VERSION ""

NS_ :

BS_:

BU_: TE DCU Dash BMS IIB ISA Interface AHRSF AHRSR GPSF GPSR

BO_ 329 TE_MAIN: 8 TE
 SG_ apps : 16|16@1+ (0.01,0) [0|10000] "percentage"  TE
 SG_ bps_pressure : 32|16@1+ (0.01,0) [0|10000] "percentage"  TE
 SG_ bps_electric : 48|16@1+ (0.01,0) [0|10000] "percentage"  TE
 SG_ cc_apps_0 : 0|1@1+ (1,0) [0|1] ""  TE
 SG_ cc_apps_1 : 1|1@1+ (1,0) [0|0] ""  TE
 SG_ cc_bps_eletric_0 : 2|1@1+ (1,0) [0|0] ""  TE
 SG_ cc_bps_pressure_0 : 3|1@1+ (1,0) [0|0] ""  TE
 SG_ cc_bps_pressure_1 : 4|1@1+ (1,0) [0|0] ""  TE
 SG_ overshoot_apps_0 : 5|1@1+ (1,0) [0|0] ""  TE
 SG_ overshoot_apps_1 : 6|1@1+ (1,0) [0|0] ""  TE
 SG_ Overshoot_BPS_eletric : 7|1@1+ (1,0) [0|0] ""  TE
 SG_ imp_apps_timer_exceeded : 8|1@1+ (1,0) [0|0] ""  TE
 SG_ imp_apps_bps_timer_exceeded : 9|1@1+ (1,0) [0|0] ""  TE
 SG_ hard_braking : 10|1@1+ (1,0) [0|0] ""  TE
 SG_ sc_motor_interlock_front : 11|1@1+ (1,0) [0|0] ""  TE
 SG_ te_verbose_mode : 12|1@1+ (1,0) [0|0] ""  TE
 SG_ implausibility_apps : 13|1@1+ (1,0) [0|0] ""  TE
 SG_ implausibility_apps_bps : 14|1@1+ (1,0) [0|0] ""  TE

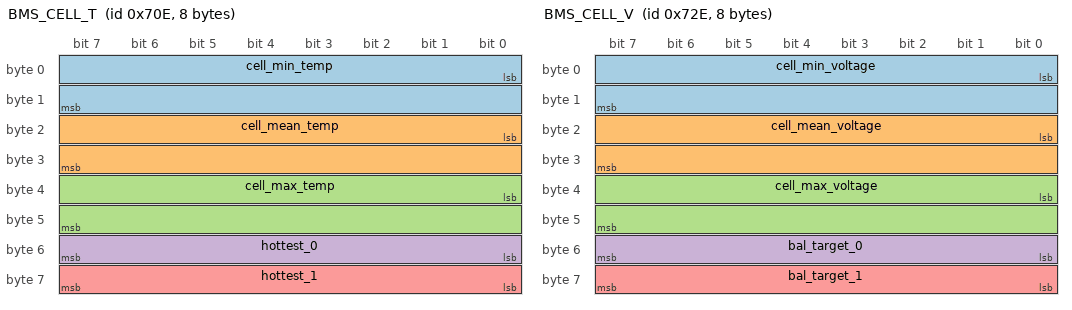
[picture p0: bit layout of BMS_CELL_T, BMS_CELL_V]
BO_ 1806 BMS_CELL_T: 8 BMS
 SG_ cell_min_temp : 0|16@1+ (0.1,0) [0|0] "C"  BMS
 SG_ cell_mean_temp : 16|16@1+ (0.1,0) [0|0] "C"  BMS
 SG_ cell_max_temp : 32|16@1+ (0.1,0) [0|0] "C"  BMS
 SG_ hottest_0 : 48|8@1+ (1,0) [0|12] ""  BMS
 SG_ hottest_1 : 56|8@1+ (1,0) [0|12] ""  BMS

BO_ 1838 BMS_CELL_V: 8 BMS
 SG_ cell_min_voltage : 0|16@1+ (1,0) [0|0] ""  BMS
 SG_ cell_mean_voltage : 16|16@1+ (1,0) [0|0] ""  BMS
 SG_ cell_max_voltage : 32|16@1+ (1,0) [0|0] ""  BMS
 SG_ bal_target_0 : 48|8@1+ (1,0) [0|0] ""  BMS
 SG_ bal_target_1 : 56|8@1+ (1,0) [0|0] ""  BMS

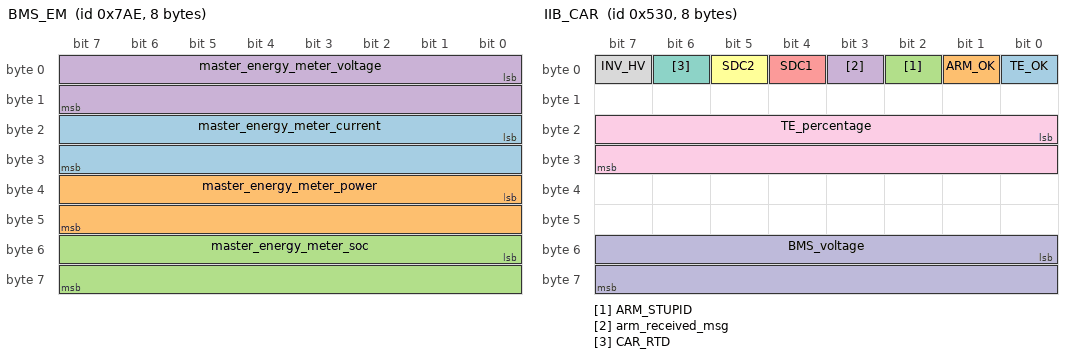
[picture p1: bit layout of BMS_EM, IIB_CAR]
BO_ 1966 BMS_EM: 8 BMS
 SG_ master_energy_meter_current : 16|16@1- (1,0) [0|0] "A"  BMS
 SG_ master_energy_meter_power : 32|16@1- (1,0) [0|0] "W"  BMS
 SG_ master_energy_meter_soc : 48|16@1+ (1,0) [0|0] "%"  BMS
 SG_ master_energy_meter_voltage : 0|16@1+ (1,0) [0|0] "V"  BMS

BO_ 398 BMS_TS_STATE: 2 BMS
 SG_ state : 0|1@1+ (1,0) [0|0] ""  BMS
 SG_ reason : 1|7@1+ (1,0) [0|0] ""  BMS

BO_ 494 BMS_STATUS: 4 BMS
 SG_ AMS_OK : 0|1@1+ (1,0) [0|0] ""  BMS
 SG_ IMD_OK : 1|1@1+ (1,0) [0|0] ""  BMS
 SG_ IMD_LATCH : 2|1@1+ (1,0) [0|0] ""  BMS
 SG_ AMS_LATCH : 3|1@1+ (1,0) [0|0] ""  BMS
 SG_ AIR_negative : 4|1@1+ (1,0) [0|0] ""  BMS
 SG_ PreChK : 6|1@1+ (1,0) [0|0] ""  BMS
 SG_ DisChK : 7|1@1+ (1,0) [0|0] ""  BMS
 SG_ SC_DCU_IMD : 8|1@1+ (1,0) [0|0] ""  BMS
 SG_ SC_IMD_AMS : 9|1@1+ (1,0) [0|0] ""  BMS
 SG_ SC_AMS_DCU : 10|1@1+ (1,0) [0|0] ""  BMS
 SG_ SC_TSMS_Relays : 11|1@1+ (1,0) [0|0] ""  BMS
 SG_ shutdown_above_minimum : 12|1@1+ (1,0) [0|0] ""  BMS
 SG_ shutdown_open : 13|1@1+ (1,0) [0|0] ""  BMS
 SG_ verbose : 14|1@1+ (1,0) [0|0] ""  BMS
 SG_ ts_on : 15|1@1+ (1,0) [0|0] ""  BMS
 SG_ AIR_positive : 5|1@1+ (1,0) [0|0] ""  BMS
 SG_ PRECH_END_SIG : 16|16@1+ (1,0) [0|0] "" Vector__XXX

BO_ 1296 IIB_LIMITS: 8 IIB
 SG_ limit_motor_num M : 14|2@1+ (1,0) [0|3] ""  IIB
 SG_ max_safety_power m0 : 0|8@1+ (1,0) [0|255] "kW"  IIB
 SG_ max_operation_power m0 : 16|16@1+ (1,0) [0|0] "kW"  IIB
 SG_ max_safety_torque m0 : 32|16@1+ (0.001,0) [0|0] "Nm"  IIB
 SG_ max_operation_torque m0 : 48|16@1+ (0.001,0) [0|0] "Nm"  IIB
 SG_ max_safety_power m1 : 0|8@1+ (1,0) [0|0] "kW"  IIB
 SG_ max_operation_power m1 : 16|16@1+ (1,0) [0|0] "kW"  IIB
 SG_ max_safety_torque m1 : 32|16@1+ (0.001,0) [0|0] "Nm"  IIB
 SG_ max_operation_torque m1 : 48|16@1+ (0.001,0) [0|0] "Nm"  IIB
 SG_ max_safety_power m2 : 0|8@1+ (1,0) [0|0] "kW"  IIB
 SG_ max_operation_power m2 : 16|16@1+ (1,0) [0|0] "kW"  IIB
 SG_ max_safety_torque m2 : 32|16@1+ (0.001,0) [0|0] "Nm"  IIB
 SG_ max_operation_torque m2 : 48|16@1+ (0.001,0) [0|0] "Nm"  IIB
 SG_ max_safety_power m3 : 0|8@1+ (1,0) [0|0] "kW"  IIB
 SG_ max_operation_power m3 : 16|16@1+ (1,0) [0|0] "kW"  IIB
 SG_ max_operation_torque m3 : 48|16@1+ (0.001,0) [0|0] "Nm"  IIB
 SG_ max_safety_torque m3: 32|16@1+ (0.001,0) [0|0] "Nm"  IIB

BO_ 1328 IIB_CAR: 8 IIB
 SG_ TE_OK : 0|1@1+ (1,0) [0|0] ""  IIB
 SG_ ARM_OK : 1|1@1+ (1,0) [0|0] ""  IIB
 SG_ ARM_STUPID : 2|1@1+ (1,0) [0|0] ""  IIB
 SG_ arm_received_msg : 3|1@1+ (1,0) [0|0] ""  IIB
 SG_ SDC1 : 4|1@1+ (1,0) [0|0] ""  IIB
 SG_ SDC2 : 5|1@1+ (1,0) [0|0] ""  IIB
 SG_ CAR_RTD : 6|1@1+ (1,0) [0|0] ""  IIB
 SG_ INV_HV : 7|1@1+ (1,0) [0|0] ""  IIB
 SG_ TE_percentage : 16|16@1+ (1,0) [0|0] "percentage"  IIB
 SG_ BMS_voltage : 48|16@1+ (1,0) [0|0] "volts"  IIB

BO_ 1232 IIB_MOTOR: 8 IIB
 SG_ info_motor_num M : 14|2@1+ (1,0) [0|3] ""  IIB
 SG_ temp_motor m0 : 0|8@1+ (1,0) [0|0] "C"  IIB
 SG_ temp_motor m1 : 0|8@1+ (1,0) [0|0] "C"  IIB
 SG_ temp_motor m2 : 0|8@1+ (1,0) [0|0] "C"  IIB
 SG_ temp_motor m3 : 0|8@1+ (1,0) [0|0] "C"  IIB
 SG_ actual_speed m0 : 16|16@1- (1,0) [0|0] "rpm"  IIB
 SG_ actual_speed m1 : 16|16@1- (1,0) [0|0] "rpm"  IIB
 SG_ actual_speed m2 : 16|16@1- (1,0) [0|0] "rpm"  IIB
 SG_ actual_speed m3 : 16|16@1- (1,0) [0|0] "rpm"  IIB
 SG_ current m0 : 32|16@1+ (1,0) [0|0] "A"  IIB
 SG_ current m1 : 32|16@1+ (1,0) [0|0] "A"  IIB
 SG_ current m2 : 32|16@1+ (1,0) [0|0] "A"  IIB
 SG_ current m3 : 32|16@1+ (1,0) [0|0] "A"  IIB
 SG_ torque m0 : 48|16@1- (1,0) [0|0] "Nm"  IIB
 SG_ torque m1 : 48|16@1- (1,0) [0|0] "Nm"  IIB
 SG_ torque m2 : 48|16@1- (1,0) [0|0] "Nm"  IIB
 SG_ torque m3 : 48|16@1- (1,0) [0|0] "Nm"  IIB

BO_ 1264 IIB_INV: 8 ISA
 SG_ inv_info_motor_num M : 3|2@1+ (1,0) [0|3] ""  IIB
 SG_ inverter_active m0 : 0|1@1+ (1,0) [0|0] ""  IIB
 SG_ inverter_active m1 : 0|1@1+ (1,0) [0|0] ""  IIB
 SG_ inverter_active m2 : 0|1@1+ (1,0) [0|0] ""  IIB
 SG_ inverter_active m3 : 0|1@1+ (1,0) [0|0] ""  IIB
 SG_ BE_1 m0 : 1|1@1+ (1,0) [0|0] ""  IIB
 SG_ BE_1 m1 : 1|1@1+ (1,0) [0|0] ""  IIB
 SG_ BE_1 m2 : 1|1@1+ (1,0) [0|0] ""  IIB
 SG_ BE_1 m3 : 1|1@1+ (1,0) [0|0] ""  IIB
 SG_ BE_2 m0 : 2|1@1+ (1,0) [0|0] ""  IIB
 SG_ BE_2 m1 : 2|1@1+ (1,0) [0|0] ""  IIB
 SG_ BE_2 m2 : 2|1@1+ (1,0) [0|0] ""  IIB
 SG_ BE_2 m3 : 2|1@1+ (1,0) [0|0] ""  IIB
 SG_ temp_igbt m0 : 16|16@1+ (1,0) [0|0] "" Vector__XXX
 SG_ temp_igbt m1 : 16|16@1+ (1,0) [0|0] ""  IIB
 SG_ temp_igbt m2 : 16|16@1+ (1,0) [0|0] "" Vector__XXX
 SG_ temp_igbt m3 : 16|16@1+ (1,0) [0|0] "" Vector__XXX
 SG_ temp_inv m0 : 32|16@1+ (1,0) [0|0] "" Vector__XXX
 SG_ temp_inv m1 : 32|16@1+ (1,0) [0|0] ""  IIB
 SG_ temp_inv m2 : 32|16@1+ (1,0) [0|0] "" Vector__XXX
 SG_ temp_inv m3 : 32|16@1+ (1,0) [0|0] "" Vector__XXX
 SG_ error_info m0 : 48|16@1+ (1,0) [0|0] "" Vector__XXX
 SG_ error_info m1 : 48|16@1+ (1,0) [0|0] ""  IIB
 SG_ error_info m2 : 48|16@1+ (1,0) [0|0] "" Vector__XXX
 SG_ error_info m3 : 48|16@1+ (1,0) [0|0] "" Vector__XXX

BO_ 2031 BMS_CELL_INF: 8 BMS
 SG_ id M : 0|8@1+ (1,0) [0|143] ""  BMS
 SG_ v_state m0 : 8|4@1+ (1,0) [0|0] ""  BMS
 SG_ v_state m1 : 8|4@1+ (1,0) [0|0] ""  BMS
 SG_ v_state m2 : 8|4@1+ (1,0) [0|0] ""  BMS
 SG_ v_state m3 : 8|4@1+ (1,0) [0|0] ""  BMS
 SG_ v_state m4 : 8|4@1+ (1,0) [0|0] ""  BMS
 SG_ v_state m5 : 8|4@1+ (1,0) [0|0] ""  BMS
 SG_ v_state m6 : 8|4@1+ (1,0) [0|0] ""  BMS
 SG_ v_state m7 : 8|4@1+ (1,0) [0|0] ""  BMS
 SG_ v_state m8 : 8|4@1+ (1,0) [0|0] ""  BMS
 SG_ v_state m9 : 8|4@1+ (1,0) [0|0] ""  BMS
 SG_ v_state m10 : 8|4@1+ (1,0) [0|0] ""  BMS
 SG_ v_state m11 : 8|4@1+ (1,0) [0|0] ""  BMS
 SG_ v_state m12 : 8|4@1+ (1,0) [0|0] ""  BMS
 SG_ v_state m13 : 8|4@1+ (1,0) [0|0] ""  BMS
 SG_ v_state m14 : 8|4@1+ (1,0) [0|0] ""  BMS
 SG_ v_state m15 : 8|4@1+ (1,0) [0|0] ""  BMS
 SG_ v_state m16 : 8|4@1+ (1,0) [0|0] ""  BMS
 SG_ v_state m17 : 8|4@1+ (1,0) [0|0] ""  BMS
 SG_ v_state m18 : 8|4@1+ (1,0) [0|0] ""  BMS
 SG_ v_state m19 : 8|4@1+ (1,0) [0|0] ""  BMS
 SG_ v_state m20 : 8|4@1+ (1,0) [0|0] ""  BMS
 SG_ v_state m21 : 8|4@1+ (1,0) [0|0] ""  BMS
 SG_ v_state m22 : 8|4@1+ (1,0) [0|0] ""  BMS
 SG_ v_state m23 : 8|4@1+ (1,0) [0|0] ""  BMS
 SG_ v_state m24 : 8|4@1+ (1,0) [0|0] ""  BMS
 SG_ v_state m25 : 8|4@1+ (1,0) [0|0] ""  BMS
 SG_ v_state m26 : 8|4@1+ (1,0) [0|0] ""  BMS
 SG_ v_state m27 : 8|4@1+ (1,0) [0|0] ""  BMS
 SG_ v_state m28 : 8|4@1+ (1,0) [0|0] ""  BMS
 SG_ v_state m29 : 8|4@1+ (1,0) [0|0] ""  BMS
 SG_ v_state m30 : 8|4@1+ (1,0) [0|0] ""  BMS
 SG_ v_state m31 : 8|4@1+ (1,0) [0|0] ""  BMS
 SG_ v_state m32 : 8|4@1+ (1,0) [0|0] ""  BMS
 SG_ v_state m33 : 8|4@1+ (1,0) [0|0] ""  BMS
 SG_ v_state m34 : 8|4@1+ (1,0) [0|0] ""  BMS
 SG_ v_state m35 : 8|4@1+ (1,0) [0|0] ""  BMS
 SG_ v_state m36 : 8|4@1+ (1,0) [0|0] ""  BMS
 SG_ v_state m37 : 8|4@1+ (1,0) [0|0] ""  BMS
 SG_ v_state m38 : 8|4@1+ (1,0) [0|0] ""  BMS
 SG_ v_state m39 : 8|4@1+ (1,0) [0|0] ""  BMS
 SG_ v_state m40 : 8|4@1+ (1,0) [0|0] ""  BMS
 SG_ v_state m41 : 8|4@1+ (1,0) [0|0] ""  BMS
 SG_ v_state m42 : 8|4@1+ (1,0) [0|0] ""  BMS
 SG_ v_state m43 : 8|4@1+ (1,0) [0|0] ""  BMS
 SG_ v_state m44 : 8|4@1+ (1,0) [0|0] ""  BMS
 SG_ v_state m45 : 8|4@1+ (1,0) [0|0] ""  BMS
 SG_ v_state m46 : 8|4@1+ (1,0) [0|0] ""  BMS
 SG_ v_state m47 : 8|4@1+ (1,0) [0|0] ""  BMS
 SG_ v_state m48 : 8|4@1+ (1,0) [0|0] ""  BMS
 SG_ v_state m49 : 8|4@1+ (1,0) [0|0] ""  BMS
 SG_ v_state m50 : 8|4@1+ (1,0) [0|0] ""  BMS
 SG_ v_state m51 : 8|4@1+ (1,0) [0|0] ""  BMS
 SG_ v_state m52 : 8|4@1+ (1,0) [0|0] ""  BMS
 SG_ v_state m53 : 8|4@1+ (1,0) [0|0] ""  BMS
 SG_ v_state m54 : 8|4@1+ (1,0) [0|0] ""  BMS
 SG_ v_state m55 : 8|4@1+ (1,0) [0|0] ""  BMS
 SG_ v_state m56 : 8|4@1+ (1,0) [0|0] ""  BMS
 SG_ v_state m57 : 8|4@1+ (1,0) [0|0] ""  BMS
 SG_ v_state m58 : 8|4@1+ (1,0) [0|0] ""  BMS
 SG_ v_state m59 : 8|4@1+ (1,0) [0|0] ""  BMS
 SG_ v_state m60 : 8|4@1+ (1,0) [0|0] ""  BMS
 SG_ v_state m61 : 8|4@1+ (1,0) [0|0] ""  BMS
 SG_ v_state m62 : 8|4@1+ (1,0) [0|0] ""  BMS
 SG_ v_state m63 : 8|4@1+ (1,0) [0|0] ""  BMS
 SG_ v_state m64 : 8|4@1+ (1,0) [0|0] ""  BMS
 SG_ v_state m65 : 8|4@1+ (1,0) [0|0] ""  BMS
 SG_ v_state m66 : 8|4@1+ (1,0) [0|0] ""  BMS
 SG_ v_state m67 : 8|4@1+ (1,0) [0|0] ""  BMS
 SG_ v_state m68 : 8|4@1+ (1,0) [0|0] ""  BMS
 SG_ v_state m69 : 8|4@1+ (1,0) [0|0] ""  BMS
 SG_ v_state m70 : 8|4@1+ (1,0) [0|0] ""  BMS
 SG_ v_state m71 : 8|4@1+ (1,0) [0|0] ""  BMS
 SG_ v_state m72 : 8|4@1+ (1,0) [0|0] ""  BMS
 SG_ v_state m73 : 8|4@1+ (1,0) [0|0] ""  BMS
 SG_ v_state m74 : 8|4@1+ (1,0) [0|0] ""  BMS
 SG_ v_state m75 : 8|4@1+ (1,0) [0|0] ""  BMS
 SG_ v_state m76 : 8|4@1+ (1,0) [0|0] ""  BMS
 SG_ v_state m77 : 8|4@1+ (1,0) [0|0] ""  BMS
 SG_ v_state m78 : 8|4@1+ (1,0) [0|0] ""  BMS
 SG_ v_state m79 : 8|4@1+ (1,0) [0|0] ""  BMS
 SG_ v_state m80 : 8|4@1+ (1,0) [0|0] ""  BMS
 SG_ v_state m81 : 8|4@1+ (1,0) [0|0] ""  BMS
 SG_ v_state m82 : 8|4@1+ (1,0) [0|0] ""  BMS
 SG_ v_state m83 : 8|4@1+ (1,0) [0|0] ""  BMS
 SG_ v_state m84 : 8|4@1+ (1,0) [0|0] ""  BMS
 SG_ v_state m85 : 8|4@1+ (1,0) [0|0] ""  BMS
 SG_ v_state m86 : 8|4@1+ (1,0) [0|0] ""  BMS
 SG_ v_state m87 : 8|4@1+ (1,0) [0|0] ""  BMS
 SG_ v_state m88 : 8|4@1+ (1,0) [0|0] ""  BMS
 SG_ v_state m89 : 8|4@1+ (1,0) [0|0] ""  BMS
 SG_ v_state m90 : 8|4@1+ (1,0) [0|0] ""  BMS
 SG_ v_state m91 : 8|4@1+ (1,0) [0|0] ""  BMS
 SG_ v_state m92 : 8|4@1+ (1,0) [0|0] ""  BMS
 SG_ v_state m93 : 8|4@1+ (1,0) [0|0] ""  BMS
 SG_ v_state m94 : 8|4@1+ (1,0) [0|0] ""  BMS
 SG_ v_state m95 : 8|4@1+ (1,0) [0|0] ""  BMS
 SG_ v_state m96 : 8|4@1+ (1,0) [0|0] ""  BMS
 SG_ v_state m97 : 8|4@1+ (1,0) [0|0] ""  BMS
 SG_ v_state m98 : 8|4@1+ (1,0) [0|0] ""  BMS
 SG_ v_state m99 : 8|4@1+ (1,0) [0|0] ""  BMS
 SG_ v_state m100 : 8|4@1+ (1,0) [0|0] ""  BMS
 SG_ v_state m101 : 8|4@1+ (1,0) [0|0] ""  BMS
 SG_ v_state m102 : 8|4@1+ (1,0) [0|0] ""  BMS
 SG_ v_state m103 : 8|4@1+ (1,0) [0|0] ""  BMS
 SG_ v_state m104 : 8|4@1+ (1,0) [0|0] ""  BMS
 SG_ v_state m105 : 8|4@1+ (1,0) [0|0] ""  BMS
 SG_ v_state m106 : 8|4@1+ (1,0) [0|0] ""  BMS
 SG_ v_state m107 : 8|4@1+ (1,0) [0|0] ""  BMS
 SG_ v_state m108 : 8|4@1+ (1,0) [0|0] ""  BMS
 SG_ v_state m109 : 8|4@1+ (1,0) [0|0] ""  BMS
 SG_ v_state m110 : 8|4@1+ (1,0) [0|0] ""  BMS
 SG_ v_state m111 : 8|4@1+ (1,0) [0|0] ""  BMS
 SG_ v_state m112 : 8|4@1+ (1,0) [0|0] ""  BMS
 SG_ v_state m113 : 8|4@1+ (1,0) [0|0] ""  BMS
 SG_ v_state m114 : 8|4@1+ (1,0) [0|0] ""  BMS
 SG_ v_state m115 : 8|4@1+ (1,0) [0|0] ""  BMS
 SG_ v_state m116 : 8|4@1+ (1,0) [0|0] ""  BMS
 SG_ v_state m117 : 8|4@1+ (1,0) [0|0] ""  BMS
 SG_ v_state m118 : 8|4@1+ (1,0) [0|0] ""  BMS
 SG_ v_state m119 : 8|4@1+ (1,0) [0|0] ""  BMS
 SG_ v_state m120 : 8|4@1+ (1,0) [0|0] ""  BMS
 SG_ v_state m121 : 8|4@1+ (1,0) [0|0] ""  BMS
 SG_ v_state m122 : 8|4@1+ (1,0) [0|0] ""  BMS
 SG_ v_state m123 : 8|4@1+ (1,0) [0|0] ""  BMS
 SG_ v_state m124 : 8|4@1+ (1,0) [0|0] ""  BMS
 SG_ v_state m125 : 8|4@1+ (1,0) [0|0] ""  BMS
 SG_ v_state m126 : 8|4@1+ (1,0) [0|0] ""  BMS
 SG_ v_state m127 : 8|4@1+ (1,0) [0|0] ""  BMS
 SG_ v_state m128 : 8|4@1+ (1,0) [0|0] ""  BMS
 SG_ v_state m129 : 8|4@1+ (1,0) [0|0] ""  BMS
 SG_ v_state m130 : 8|4@1+ (1,0) [0|0] ""  BMS
 SG_ v_state m131 : 8|4@1+ (1,0) [0|0] ""  BMS
 SG_ v_state m132 : 8|4@1+ (1,0) [0|0] ""  BMS
 SG_ v_state m133 : 8|4@1+ (1,0) [0|0] ""  BMS
 SG_ v_state m134 : 8|4@1+ (1,0) [0|0] ""  BMS
 SG_ v_state m135 : 8|4@1+ (1,0) [0|0] ""  BMS
 SG_ v_state m136 : 8|4@1+ (1,0) [0|0] ""  BMS
 SG_ v_state m137 : 8|4@1+ (1,0) [0|0] ""  BMS
 SG_ v_state m138 : 8|4@1+ (1,0) [0|0] ""  BMS
 SG_ v_state m139 : 8|4@1+ (1,0) [0|0] ""  BMS
 SG_ v_state m140 : 8|4@1+ (1,0) [0|0] ""  BMS
 SG_ v_state m141 : 8|4@1+ (1,0) [0|0] ""  BMS
 SG_ v_state m142 : 8|4@1+ (1,0) [0|0] ""  BMS
 SG_ v_state m143 : 8|4@1+ (1,0) [0|0] ""  BMS
 SG_ t_state m0 : 12|4@1+ (1,0) [0|0] ""  BMS
 SG_ t_state m1 : 12|4@1+ (1,0) [0|0] ""  BMS
 SG_ t_state m2 : 12|4@1+ (1,0) [0|0] ""  BMS
 SG_ t_state m3 : 12|4@1+ (1,0) [0|0] ""  BMS
 SG_ t_state m4 : 12|4@1+ (1,0) [0|0] ""  BMS
 SG_ t_state m5 : 12|4@1+ (1,0) [0|0] ""  BMS
 SG_ t_state m6 : 12|4@1+ (1,0) [0|0] ""  BMS
 SG_ t_state m7 : 12|4@1+ (1,0) [0|0] ""  BMS
 SG_ t_state m8 : 12|4@1+ (1,0) [0|0] ""  BMS
 SG_ t_state m9 : 12|4@1+ (1,0) [0|0] ""  BMS
 SG_ t_state m10 : 12|4@1+ (1,0) [0|0] ""  BMS
 SG_ t_state m11 : 12|4@1+ (1,0) [0|0] ""  BMS
 SG_ t_state m12 : 12|4@1+ (1,0) [0|0] ""  BMS
 SG_ t_state m13 : 12|4@1+ (1,0) [0|0] ""  BMS
 SG_ t_state m14 : 12|4@1+ (1,0) [0|0] ""  BMS
 SG_ t_state m15 : 12|4@1+ (1,0) [0|0] ""  BMS
 SG_ t_state m16 : 12|4@1+ (1,0) [0|0] ""  BMS
 SG_ t_state m17 : 12|4@1+ (1,0) [0|0] ""  BMS
 SG_ t_state m18 : 12|4@1+ (1,0) [0|0] ""  BMS
 SG_ t_state m19 : 12|4@1+ (1,0) [0|0] ""  BMS
 SG_ t_state m20 : 12|4@1+ (1,0) [0|0] ""  BMS
 SG_ t_state m21 : 12|4@1+ (1,0) [0|0] ""  BMS
 SG_ t_state m22 : 12|4@1+ (1,0) [0|0] ""  BMS
 SG_ t_state m23 : 12|4@1+ (1,0) [0|0] ""  BMS
 SG_ t_state m24 : 12|4@1+ (1,0) [0|0] ""  BMS
 SG_ t_state m25 : 12|4@1+ (1,0) [0|0] ""  BMS
 SG_ t_state m26 : 12|4@1+ (1,0) [0|0] ""  BMS
 SG_ t_state m27 : 12|4@1+ (1,0) [0|0] ""  BMS
 SG_ t_state m28 : 12|4@1+ (1,0) [0|0] ""  BMS
 SG_ t_state m29 : 12|4@1+ (1,0) [0|0] ""  BMS
 SG_ t_state m30 : 12|4@1+ (1,0) [0|0] ""  BMS
 SG_ t_state m31 : 12|4@1+ (1,0) [0|0] ""  BMS
 SG_ t_state m32 : 12|4@1+ (1,0) [0|0] ""  BMS
 SG_ t_state m33 : 12|4@1+ (1,0) [0|0] ""  BMS
 SG_ t_state m34 : 12|4@1+ (1,0) [0|0] ""  BMS
 SG_ t_state m35 : 12|4@1+ (1,0) [0|0] ""  BMS
 SG_ t_state m36 : 12|4@1+ (1,0) [0|0] ""  BMS
 SG_ t_state m37 : 12|4@1+ (1,0) [0|0] ""  BMS
 SG_ t_state m38 : 12|4@1+ (1,0) [0|0] ""  BMS
 SG_ t_state m39 : 12|4@1+ (1,0) [0|0] ""  BMS
 SG_ t_state m40 : 12|4@1+ (1,0) [0|0] ""  BMS
 SG_ t_state m41 : 12|4@1+ (1,0) [0|0] ""  BMS
 SG_ t_state m42 : 12|4@1+ (1,0) [0|0] ""  BMS
 SG_ t_state m43 : 12|4@1+ (1,0) [0|0] ""  BMS
 SG_ t_state m44 : 12|4@1+ (1,0) [0|0] ""  BMS
 SG_ t_state m45 : 12|4@1+ (1,0) [0|0] ""  BMS
 SG_ t_state m46 : 12|4@1+ (1,0) [0|0] ""  BMS
 SG_ t_state m47 : 12|4@1+ (1,0) [0|0] ""  BMS
 SG_ t_state m48 : 12|4@1+ (1,0) [0|0] ""  BMS
 SG_ t_state m49 : 12|4@1+ (1,0) [0|0] ""  BMS
 SG_ t_state m50 : 12|4@1+ (1,0) [0|0] ""  BMS
 SG_ t_state m51 : 12|4@1+ (1,0) [0|0] ""  BMS
 SG_ t_state m52 : 12|4@1+ (1,0) [0|0] ""  BMS
 SG_ t_state m53 : 12|4@1+ (1,0) [0|0] ""  BMS
 SG_ t_state m54 : 12|4@1+ (1,0) [0|0] ""  BMS
 SG_ t_state m55 : 12|4@1+ (1,0) [0|0] ""  BMS
 SG_ t_state m56 : 12|4@1+ (1,0) [0|0] ""  BMS
 SG_ t_state m57 : 12|4@1+ (1,0) [0|0] ""  BMS
 SG_ t_state m58 : 12|4@1+ (1,0) [0|0] ""  BMS
 SG_ t_state m59 : 12|4@1+ (1,0) [0|0] ""  BMS
 SG_ t_state m60 : 12|4@1+ (1,0) [0|0] ""  BMS
 SG_ t_state m61 : 12|4@1+ (1,0) [0|0] ""  BMS
 SG_ t_state m62 : 12|4@1+ (1,0) [0|0] ""  BMS
 SG_ t_state m63 : 12|4@1+ (1,0) [0|0] ""  BMS
 SG_ t_state m64 : 12|4@1+ (1,0) [0|0] ""  BMS
 SG_ t_state m65 : 12|4@1+ (1,0) [0|0] ""  BMS
 SG_ t_state m66 : 12|4@1+ (1,0) [0|0] ""  BMS
 SG_ t_state m67 : 12|4@1+ (1,0) [0|0] ""  BMS
 SG_ t_state m68 : 12|4@1+ (1,0) [0|0] ""  BMS
 SG_ t_state m69 : 12|4@1+ (1,0) [0|0] ""  BMS
 SG_ t_state m70 : 12|4@1+ (1,0) [0|0] ""  BMS
 SG_ t_state m71 : 12|4@1+ (1,0) [0|0] ""  BMS
 SG_ t_state m72 : 12|4@1+ (1,0) [0|0] ""  BMS
 SG_ t_state m73 : 12|4@1+ (1,0) [0|0] ""  BMS
 SG_ t_state m74 : 12|4@1+ (1,0) [0|0] ""  BMS
 SG_ t_state m75 : 12|4@1+ (1,0) [0|0] ""  BMS
 SG_ t_state m76 : 12|4@1+ (1,0) [0|0] ""  BMS
 SG_ t_state m77 : 12|4@1+ (1,0) [0|0] ""  BMS
 SG_ t_state m78 : 12|4@1+ (1,0) [0|0] ""  BMS
 SG_ t_state m79 : 12|4@1+ (1,0) [0|0] ""  BMS
 SG_ t_state m80 : 12|4@1+ (1,0) [0|0] ""  BMS
 SG_ t_state m81 : 12|4@1+ (1,0) [0|0] ""  BMS
 SG_ t_state m82 : 12|4@1+ (1,0) [0|0] ""  BMS
 SG_ t_state m83 : 12|4@1+ (1,0) [0|0] ""  BMS
 SG_ t_state m84 : 12|4@1+ (1,0) [0|0] ""  BMS
 SG_ t_state m85 : 12|4@1+ (1,0) [0|0] ""  BMS
 SG_ t_state m86 : 12|4@1+ (1,0) [0|0] ""  BMS
 SG_ t_state m87 : 12|4@1+ (1,0) [0|0] ""  BMS
 SG_ t_state m88 : 12|4@1+ (1,0) [0|0] ""  BMS
 SG_ t_state m89 : 12|4@1+ (1,0) [0|0] ""  BMS
 SG_ t_state m90 : 12|4@1+ (1,0) [0|0] ""  BMS
 SG_ t_state m91 : 12|4@1+ (1,0) [0|0] ""  BMS
 SG_ t_state m92 : 12|4@1+ (1,0) [0|0] ""  BMS
 SG_ t_state m93 : 12|4@1+ (1,0) [0|0] ""  BMS
 SG_ t_state m94 : 12|4@1+ (1,0) [0|0] ""  BMS
 SG_ t_state m95 : 12|4@1+ (1,0) [0|0] ""  BMS
 SG_ t_state m96 : 12|4@1+ (1,0) [0|0] ""  BMS
 SG_ t_state m97 : 12|4@1+ (1,0) [0|0] ""  BMS
 SG_ t_state m98 : 12|4@1+ (1,0) [0|0] ""  BMS
 SG_ t_state m99 : 12|4@1+ (1,0) [0|0] ""  BMS
 SG_ t_state m100 : 12|4@1+ (1,0) [0|0] ""  BMS
 SG_ t_state m101 : 12|4@1+ (1,0) [0|0] ""  BMS
 SG_ t_state m102 : 12|4@1+ (1,0) [0|0] ""  BMS
 SG_ t_state m103 : 12|4@1+ (1,0) [0|0] ""  BMS
 SG_ t_state m104 : 12|4@1+ (1,0) [0|0] ""  BMS
 SG_ t_state m105 : 12|4@1+ (1,0) [0|0] ""  BMS
 SG_ t_state m106 : 12|4@1+ (1,0) [0|0] ""  BMS
 SG_ t_state m107 : 12|4@1+ (1,0) [0|0] ""  BMS
 SG_ t_state m108 : 12|4@1+ (1,0) [0|0] ""  BMS
 SG_ t_state m109 : 12|4@1+ (1,0) [0|0] ""  BMS
 SG_ t_state m110 : 12|4@1+ (1,0) [0|0] ""  BMS
 SG_ t_state m111 : 12|4@1+ (1,0) [0|0] ""  BMS
 SG_ t_state m112 : 12|4@1+ (1,0) [0|0] ""  BMS
 SG_ t_state m113 : 12|4@1+ (1,0) [0|0] ""  BMS
 SG_ t_state m114 : 12|4@1+ (1,0) [0|0] ""  BMS
 SG_ t_state m115 : 12|4@1+ (1,0) [0|0] ""  BMS
 SG_ t_state m116 : 12|4@1+ (1,0) [0|0] ""  BMS
 SG_ t_state m117 : 12|4@1+ (1,0) [0|0] ""  BMS
 SG_ t_state m118 : 12|4@1+ (1,0) [0|0] ""  BMS
 SG_ t_state m119 : 12|4@1+ (1,0) [0|0] ""  BMS
 SG_ t_state m120 : 12|4@1+ (1,0) [0|0] ""  BMS
 SG_ t_state m121 : 12|4@1+ (1,0) [0|0] ""  BMS
 SG_ t_state m122 : 12|4@1+ (1,0) [0|0] ""  BMS
 SG_ t_state m123 : 12|4@1+ (1,0) [0|0] ""  BMS
 SG_ t_state m124 : 12|4@1+ (1,0) [0|0] ""  BMS
 SG_ t_state m125 : 12|4@1+ (1,0) [0|0] ""  BMS
 SG_ t_state m126 : 12|4@1+ (1,0) [0|0] ""  BMS
 SG_ t_state m127 : 12|4@1+ (1,0) [0|0] ""  BMS
 SG_ t_state m128 : 12|4@1+ (1,0) [0|0] ""  BMS
 SG_ t_state m129 : 12|4@1+ (1,0) [0|0] ""  BMS
 SG_ t_state m130 : 12|4@1+ (1,0) [0|0] ""  BMS
 SG_ t_state m131 : 12|4@1+ (1,0) [0|0] ""  BMS
 SG_ t_state m132 : 12|4@1+ (1,0) [0|0] ""  BMS
 SG_ t_state m133 : 12|4@1+ (1,0) [0|0] ""  BMS
 SG_ t_state m134 : 12|4@1+ (1,0) [0|0] ""  BMS
 SG_ t_state m135 : 12|4@1+ (1,0) [0|0] ""  BMS
 SG_ t_state m136 : 12|4@1+ (1,0) [0|0] ""  BMS
 SG_ t_state m137 : 12|4@1+ (1,0) [0|0] ""  BMS
 SG_ t_state m138 : 12|4@1+ (1,0) [0|0] ""  BMS
 SG_ t_state m139 : 12|4@1+ (1,0) [0|0] ""  BMS
 SG_ t_state m140 : 12|4@1+ (1,0) [0|0] ""  BMS
 SG_ t_state m141 : 12|4@1+ (1,0) [0|0] ""  BMS
 SG_ t_state m142 : 12|4@1+ (1,0) [0|0] ""  BMS
 SG_ t_state m143 : 12|4@1+ (1,0) [0|0] ""  BMS
 SG_ v m0 : 16|16@1+ (1,0) [0|0] "V"  BMS
 SG_ v m1 : 16|16@1+ (1,0) [0|0] "V"  BMS
 SG_ v m2 : 16|16@1+ (1,0) [0|0] "V"  BMS
 SG_ v m3 : 16|16@1+ (1,0) [0|0] "V"  BMS
 SG_ v m4 : 16|16@1+ (1,0) [0|0] "V"  BMS
 SG_ v m5 : 16|16@1+ (1,0) [0|0] "V"  BMS
 SG_ v m6 : 16|16@1+ (1,0) [0|0] "V"  BMS
 SG_ v m7 : 16|16@1+ (1,0) [0|0] "V"  BMS
 SG_ v m8 : 16|16@1+ (1,0) [0|0] "V"  BMS
 SG_ v m9 : 16|16@1+ (1,0) [0|0] "V"  BMS
 SG_ v m10 : 16|16@1+ (1,0) [0|0] "V"  BMS
 SG_ v m11 : 16|16@1+ (1,0) [0|0] "V"  BMS
 SG_ v m12 : 16|16@1+ (1,0) [0|0] "V"  BMS
 SG_ v m13 : 16|16@1+ (1,0) [0|0] "V"  BMS
 SG_ v m14 : 16|16@1+ (1,0) [0|0] "V"  BMS
 SG_ v m15 : 16|16@1+ (1,0) [0|0] "V"  BMS
 SG_ v m16 : 16|16@1+ (1,0) [0|0] "V"  BMS
 SG_ v m17 : 16|16@1+ (1,0) [0|0] "V"  BMS
 SG_ v m18 : 16|16@1+ (1,0) [0|0] "V"  BMS
 SG_ v m19 : 16|16@1+ (1,0) [0|0] "V"  BMS
 SG_ v m20 : 16|16@1+ (1,0) [0|0] "V"  BMS
 SG_ v m21 : 16|16@1+ (1,0) [0|0] "V"  BMS
 SG_ v m22 : 16|16@1+ (1,0) [0|0] "V"  BMS
 SG_ v m23 : 16|16@1+ (1,0) [0|0] "V"  BMS
 SG_ v m24 : 16|16@1+ (1,0) [0|0] "V"  BMS
 SG_ v m25 : 16|16@1+ (1,0) [0|0] "V"  BMS
 SG_ v m26 : 16|16@1+ (1,0) [0|0] "V"  BMS
 SG_ v m27 : 16|16@1+ (1,0) [0|0] "V"  BMS
 SG_ v m28 : 16|16@1+ (1,0) [0|0] "V"  BMS
 SG_ v m29 : 16|16@1+ (1,0) [0|0] "V"  BMS
 SG_ v m30 : 16|16@1+ (1,0) [0|0] "V"  BMS
 SG_ v m31 : 16|16@1+ (1,0) [0|0] "V"  BMS
 SG_ v m32 : 16|16@1+ (1,0) [0|0] "V"  BMS
 SG_ v m33 : 16|16@1+ (1,0) [0|0] "V"  BMS
 SG_ v m34 : 16|16@1+ (1,0) [0|0] "V"  BMS
 SG_ v m35 : 16|16@1+ (1,0) [0|0] "V"  BMS
 SG_ v m36 : 16|16@1+ (1,0) [0|0] "V"  BMS
 SG_ v m37 : 16|16@1+ (1,0) [0|0] "V"  BMS
 SG_ v m38 : 16|16@1+ (1,0) [0|0] "V"  BMS
 SG_ v m39 : 16|16@1+ (1,0) [0|0] "V"  BMS
 SG_ v m40 : 16|16@1+ (1,0) [0|0] "V"  BMS
 SG_ v m41 : 16|16@1+ (1,0) [0|0] "V"  BMS
 SG_ v m42 : 16|16@1+ (1,0) [0|0] "V"  BMS
 SG_ v m43 : 16|16@1+ (1,0) [0|0] "V"  BMS
 SG_ v m44 : 16|16@1+ (1,0) [0|0] "V"  BMS
 SG_ v m45 : 16|16@1+ (1,0) [0|0] "V"  BMS
 SG_ v m46 : 16|16@1+ (1,0) [0|0] "V"  BMS
 SG_ v m47 : 16|16@1+ (1,0) [0|0] "V"  BMS
 SG_ v m48 : 16|16@1+ (1,0) [0|0] "V"  BMS
 SG_ v m49 : 16|16@1+ (1,0) [0|0] "V"  BMS
 SG_ v m50 : 16|16@1+ (1,0) [0|0] "V"  BMS
 SG_ v m51 : 16|16@1+ (1,0) [0|0] "V"  BMS
 SG_ v m52 : 16|16@1+ (1,0) [0|0] "V"  BMS
 SG_ v m53 : 16|16@1+ (1,0) [0|0] "V"  BMS
 SG_ v m54 : 16|16@1+ (1,0) [0|0] "V"  BMS
 SG_ v m55 : 16|16@1+ (1,0) [0|0] "V"  BMS
 SG_ v m56 : 16|16@1+ (1,0) [0|0] "V"  BMS
 SG_ v m57 : 16|16@1+ (1,0) [0|0] "V"  BMS
 SG_ v m58 : 16|16@1+ (1,0) [0|0] "V"  BMS
 SG_ v m59 : 16|16@1+ (1,0) [0|0] "V"  BMS
 SG_ v m60 : 16|16@1+ (1,0) [0|0] "V"  BMS
 SG_ v m61 : 16|16@1+ (1,0) [0|0] "V"  BMS
 SG_ v m62 : 16|16@1+ (1,0) [0|0] "V"  BMS
 SG_ v m63 : 16|16@1+ (1,0) [0|0] "V"  BMS
 SG_ v m64 : 16|16@1+ (1,0) [0|0] "V"  BMS
 SG_ v m65 : 16|16@1+ (1,0) [0|0] "V"  BMS
 SG_ v m66 : 16|16@1+ (1,0) [0|0] "V"  BMS
 SG_ v m67 : 16|16@1+ (1,0) [0|0] "V"  BMS
 SG_ v m68 : 16|16@1+ (1,0) [0|0] "V"  BMS
 SG_ v m69 : 16|16@1+ (1,0) [0|0] "V"  BMS
 SG_ v m70 : 16|16@1+ (1,0) [0|0] "V"  BMS
 SG_ v m71 : 16|16@1+ (1,0) [0|0] "V"  BMS
 SG_ v m72 : 16|16@1+ (1,0) [0|0] "V"  BMS
 SG_ v m73 : 16|16@1+ (1,0) [0|0] "V"  BMS
 SG_ v m74 : 16|16@1+ (1,0) [0|0] "V"  BMS
 SG_ v m75 : 16|16@1+ (1,0) [0|0] "V"  BMS
 SG_ v m76 : 16|16@1+ (1,0) [0|0] "V"  BMS
 SG_ v m77 : 16|16@1+ (1,0) [0|0] "V"  BMS
 SG_ v m78 : 16|16@1+ (1,0) [0|0] "V"  BMS
 SG_ v m79 : 16|16@1+ (1,0) [0|0] "V"  BMS
 SG_ v m80 : 16|16@1+ (1,0) [0|0] "V"  BMS
 SG_ v m81 : 16|16@1+ (1,0) [0|0] "V"  BMS
 SG_ v m82 : 16|16@1+ (1,0) [0|0] "V"  BMS
 SG_ v m83 : 16|16@1+ (1,0) [0|0] "V"  BMS
 SG_ v m84 : 16|16@1+ (1,0) [0|0] "V"  BMS
 SG_ v m85 : 16|16@1+ (1,0) [0|0] "V"  BMS
 SG_ v m86 : 16|16@1+ (1,0) [0|0] "V"  BMS
 SG_ v m87 : 16|16@1+ (1,0) [0|0] "V"  BMS
 SG_ v m88 : 16|16@1+ (1,0) [0|0] "V"  BMS
 SG_ v m89 : 16|16@1+ (1,0) [0|0] "V"  BMS
 SG_ v m90 : 16|16@1+ (1,0) [0|0] "V"  BMS
 SG_ v m91 : 16|16@1+ (1,0) [0|0] "V"  BMS
 SG_ v m92 : 16|16@1+ (1,0) [0|0] "V"  BMS
 SG_ v m93 : 16|16@1+ (1,0) [0|0] "V"  BMS
 SG_ v m94 : 16|16@1+ (1,0) [0|0] "V"  BMS
 SG_ v m95 : 16|16@1+ (1,0) [0|0] "V"  BMS
 SG_ v m96 : 16|16@1+ (1,0) [0|0] "V"  BMS
 SG_ v m97 : 16|16@1+ (1,0) [0|0] "V"  BMS
 SG_ v m98 : 16|16@1+ (1,0) [0|0] "V"  BMS
 SG_ v m99 : 16|16@1+ (1,0) [0|0] "V"  BMS
 SG_ v m100 : 16|16@1+ (1,0) [0|0] "V"  BMS
 SG_ v m101 : 16|16@1+ (1,0) [0|0] "V"  BMS
 SG_ v m102 : 16|16@1+ (1,0) [0|0] "V"  BMS
 SG_ v m103 : 16|16@1+ (1,0) [0|0] "V"  BMS
 SG_ v m104 : 16|16@1+ (1,0) [0|0] "V"  BMS
 SG_ v m105 : 16|16@1+ (1,0) [0|0] "V"  BMS
 SG_ v m106 : 16|16@1+ (1,0) [0|0] "V"  BMS
 SG_ v m107 : 16|16@1+ (1,0) [0|0] "V"  BMS
 SG_ v m108 : 16|16@1+ (1,0) [0|0] "V"  BMS
 SG_ v m109 : 16|16@1+ (1,0) [0|0] "V"  BMS
 SG_ v m110 : 16|16@1+ (1,0) [0|0] "V"  BMS
 SG_ v m111 : 16|16@1+ (1,0) [0|0] "V"  BMS
 SG_ v m112 : 16|16@1+ (1,0) [0|0] "V"  BMS
 SG_ v m113 : 16|16@1+ (1,0) [0|0] "V"  BMS
 SG_ v m114 : 16|16@1+ (1,0) [0|0] "V"  BMS
 SG_ v m115 : 16|16@1+ (1,0) [0|0] "V"  BMS
 SG_ v m116 : 16|16@1+ (1,0) [0|0] "V"  BMS
 SG_ v m117 : 16|16@1+ (1,0) [0|0] "V"  BMS
 SG_ v m118 : 16|16@1+ (1,0) [0|0] "V"  BMS
 SG_ v m119 : 16|16@1+ (1,0) [0|0] "V"  BMS
 SG_ v m120 : 16|16@1+ (1,0) [0|0] "V"  BMS
 SG_ v m121 : 16|16@1+ (1,0) [0|0] "V"  BMS
 SG_ v m122 : 16|16@1+ (1,0) [0|0] "V"  BMS
 SG_ v m123 : 16|16@1+ (1,0) [0|0] "V"  BMS
 SG_ v m124 : 16|16@1+ (1,0) [0|0] "V"  BMS
 SG_ v m125 : 16|16@1+ (1,0) [0|0] "V"  BMS
 SG_ v m126 : 16|16@1+ (1,0) [0|0] "V"  BMS
 SG_ v m127 : 16|16@1+ (1,0) [0|0] "V"  BMS
 SG_ v m128 : 16|16@1+ (1,0) [0|0] "V"  BMS
 SG_ v m129 : 16|16@1+ (1,0) [0|0] "V"  BMS
 SG_ v m130 : 16|16@1+ (1,0) [0|0] "V"  BMS
 SG_ v m131 : 16|16@1+ (1,0) [0|0] "V"  BMS
 SG_ v m132 : 16|16@1+ (1,0) [0|0] "V"  BMS
 SG_ v m133 : 16|16@1+ (1,0) [0|0] "V"  BMS
 SG_ v m134 : 16|16@1+ (1,0) [0|0] "V"  BMS
 SG_ v m135 : 16|16@1+ (1,0) [0|0] "V"  BMS
 SG_ v m136 : 16|16@1+ (1,0) [0|0] "V"  BMS
 SG_ v m137 : 16|16@1+ (1,0) [0|0] "V"  BMS
 SG_ v m138 : 16|16@1+ (1,0) [0|0] "V"  BMS
 SG_ v m139 : 16|16@1+ (1,0) [0|0] "V"  BMS
 SG_ v m140 : 16|16@1+ (1,0) [0|0] "V"  BMS
 SG_ v m141 : 16|16@1+ (1,0) [0|0] "V"  BMS
 SG_ v m142 : 16|16@1+ (1,0) [0|0] "V"  BMS
 SG_ v m143 : 16|16@1+ (1,0) [0|0] "V"  BMS
 SG_ t m0 : 32|16@1+ (0.1,0) [0|0] "C"  BMS
 SG_ t m1 : 32|16@1+ (0.1,0) [0|0] "C"  BMS
 SG_ t m2 : 32|16@1+ (0.1,0) [0|0] "C"  BMS
 SG_ t m3 : 32|16@1+ (0.1,0) [0|0] "C"  BMS
 SG_ t m4 : 32|16@1+ (0.1,0) [0|0] "C"  BMS
 SG_ t m5 : 32|16@1+ (0.1,0) [0|0] "C"  BMS
 SG_ t m6 : 32|16@1+ (0.1,0) [0|0] "C"  BMS
 SG_ t m7 : 32|16@1+ (0.1,0) [0|0] "C"  BMS
 SG_ t m8 : 32|16@1+ (0.1,0) [0|0] "C"  BMS
 SG_ t m9 : 32|16@1+ (0.1,0) [0|0] "C"  BMS
 SG_ t m10 : 32|16@1+ (0.1,0) [0|0] "C"  BMS
 SG_ t m11 : 32|16@1+ (0.1,0) [0|0] "C"  BMS
 SG_ t m12 : 32|16@1+ (0.1,0) [0|0] "C"  BMS
 SG_ t m13 : 32|16@1+ (0.1,0) [0|0] "C"  BMS
 SG_ t m14 : 32|16@1+ (0.1,0) [0|0] "C"  BMS
 SG_ t m15 : 32|16@1+ (0.1,0) [0|0] "C"  BMS
 SG_ t m16 : 32|16@1+ (0.1,0) [0|0] "C"  BMS
 SG_ t m17 : 32|16@1+ (0.1,0) [0|0] "C"  BMS
 SG_ t m18 : 32|16@1+ (0.1,0) [0|0] "C"  BMS
 SG_ t m19 : 32|16@1+ (0.1,0) [0|0] "C"  BMS
 SG_ t m20 : 32|16@1+ (0.1,0) [0|0] "C"  BMS
 SG_ t m21 : 32|16@1+ (0.1,0) [0|0] "C"  BMS
 SG_ t m22 : 32|16@1+ (0.1,0) [0|0] "C"  BMS
 SG_ t m23 : 32|16@1+ (0.1,0) [0|0] "C"  BMS
 SG_ t m24 : 32|16@1+ (0.1,0) [0|0] "C"  BMS
 SG_ t m25 : 32|16@1+ (0.1,0) [0|0] "C"  BMS
 SG_ t m26 : 32|16@1+ (0.1,0) [0|0] "C"  BMS
 SG_ t m27 : 32|16@1+ (0.1,0) [0|0] "C"  BMS
 SG_ t m28 : 32|16@1+ (0.1,0) [0|0] "C"  BMS
 SG_ t m29 : 32|16@1+ (0.1,0) [0|0] "C"  BMS
 SG_ t m30 : 32|16@1+ (0.1,0) [0|0] "C"  BMS
 SG_ t m31 : 32|16@1+ (0.1,0) [0|0] "C"  BMS
 SG_ t m32 : 32|16@1+ (0.1,0) [0|0] "C"  BMS
 SG_ t m33 : 32|16@1+ (0.1,0) [0|0] "C"  BMS
 SG_ t m34 : 32|16@1+ (0.1,0) [0|0] "C"  BMS
 SG_ t m35 : 32|16@1+ (0.1,0) [0|0] "C"  BMS
 SG_ t m36 : 32|16@1+ (0.1,0) [0|0] "C"  BMS
 SG_ t m37 : 32|16@1+ (0.1,0) [0|0] "C"  BMS
 SG_ t m38 : 32|16@1+ (0.1,0) [0|0] "C"  BMS
 SG_ t m39 : 32|16@1+ (0.1,0) [0|0] "C"  BMS
 SG_ t m40 : 32|16@1+ (0.1,0) [0|0] "C"  BMS
 SG_ t m41 : 32|16@1+ (0.1,0) [0|0] "C"  BMS
 SG_ t m42 : 32|16@1+ (0.1,0) [0|0] "C"  BMS
 SG_ t m43 : 32|16@1+ (0.1,0) [0|0] "C"  BMS
 SG_ t m44 : 32|16@1+ (0.1,0) [0|0] "C"  BMS
 SG_ t m45 : 32|16@1+ (0.1,0) [0|0] "C"  BMS
 SG_ t m46 : 32|16@1+ (0.1,0) [0|0] "C"  BMS
 SG_ t m47 : 32|16@1+ (0.1,0) [0|0] "C"  BMS
 SG_ t m48 : 32|16@1+ (0.1,0) [0|0] "C"  BMS
 SG_ t m49 : 32|16@1+ (0.1,0) [0|0] "C"  BMS
 SG_ t m50 : 32|16@1+ (0.1,0) [0|0] "C"  BMS
 SG_ t m51 : 32|16@1+ (0.1,0) [0|0] "C"  BMS
 SG_ t m52 : 32|16@1+ (0.1,0) [0|0] "C"  BMS
 SG_ t m53 : 32|16@1+ (0.1,0) [0|0] "C"  BMS
 SG_ t m54 : 32|16@1+ (0.1,0) [0|0] "C"  BMS
 SG_ t m55 : 32|16@1+ (0.1,0) [0|0] "C"  BMS
 SG_ t m56 : 32|16@1+ (0.1,0) [0|0] "C"  BMS
 SG_ t m57 : 32|16@1+ (0.1,0) [0|0] "C"  BMS
 SG_ t m58 : 32|16@1+ (0.1,0) [0|0] "C"  BMS
 SG_ t m59 : 32|16@1+ (0.1,0) [0|0] "C"  BMS
 SG_ t m60 : 32|16@1+ (0.1,0) [0|0] "C"  BMS
 SG_ t m61 : 32|16@1+ (0.1,0) [0|0] "C"  BMS
 SG_ t m62 : 32|16@1+ (0.1,0) [0|0] "C"  BMS
 SG_ t m63 : 32|16@1+ (0.1,0) [0|0] "C"  BMS
 SG_ t m64 : 32|16@1+ (0.1,0) [0|0] "C"  BMS
 SG_ t m65 : 32|16@1+ (0.1,0) [0|0] "C"  BMS
 SG_ t m66 : 32|16@1+ (0.1,0) [0|0] "C"  BMS
 SG_ t m67 : 32|16@1+ (0.1,0) [0|0] "C"  BMS
 SG_ t m68 : 32|16@1+ (0.1,0) [0|0] "C"  BMS
 SG_ t m69 : 32|16@1+ (0.1,0) [0|0] "C"  BMS
 SG_ t m70 : 32|16@1+ (0.1,0) [0|0] "C"  BMS
 SG_ t m71 : 32|16@1+ (0.1,0) [0|0] "C"  BMS
 SG_ t m72 : 32|16@1+ (0.1,0) [0|0] "C"  BMS
 SG_ t m73 : 32|16@1+ (0.1,0) [0|0] "C"  BMS
 SG_ t m74 : 32|16@1+ (0.1,0) [0|0] "C"  BMS
 SG_ t m75 : 32|16@1+ (0.1,0) [0|0] "C"  BMS
 SG_ t m76 : 32|16@1+ (0.1,0) [0|0] "C"  BMS
 SG_ t m77 : 32|16@1+ (0.1,0) [0|0] "C"  BMS
 SG_ t m78 : 32|16@1+ (0.1,0) [0|0] "C"  BMS
 SG_ t m79 : 32|16@1+ (0.1,0) [0|0] "C"  BMS
 SG_ t m80 : 32|16@1+ (0.1,0) [0|0] "C"  BMS
 SG_ t m81 : 32|16@1+ (0.1,0) [0|0] "C"  BMS
 SG_ t m82 : 32|16@1+ (0.1,0) [0|0] "C"  BMS
 SG_ t m83 : 32|16@1+ (0.1,0) [0|0] "C"  BMS
 SG_ t m84 : 32|16@1+ (0.1,0) [0|0] "C"  BMS
 SG_ t m85 : 32|16@1+ (0.1,0) [0|0] "C"  BMS
 SG_ t m86 : 32|16@1+ (0.1,0) [0|0] "C"  BMS
 SG_ t m87 : 32|16@1+ (0.1,0) [0|0] "C"  BMS
 SG_ t m88 : 32|16@1+ (0.1,0) [0|0] "C"  BMS
 SG_ t m89 : 32|16@1+ (0.1,0) [0|0] "C"  BMS
 SG_ t m90 : 32|16@1+ (0.1,0) [0|0] "C"  BMS
 SG_ t m91 : 32|16@1+ (0.1,0) [0|0] "C"  BMS
 SG_ t m92 : 32|16@1+ (0.1,0) [0|0] "C"  BMS
 SG_ t m93 : 32|16@1+ (0.1,0) [0|0] "C"  BMS
 SG_ t m94 : 32|16@1+ (0.1,0) [0|0] "C"  BMS
 SG_ t m95 : 32|16@1+ (0.1,0) [0|0] "C"  BMS
 SG_ t m96 : 32|16@1+ (0.1,0) [0|0] "C"  BMS
 SG_ t m97 : 32|16@1+ (0.1,0) [0|0] "C"  BMS
 SG_ t m98 : 32|16@1+ (0.1,0) [0|0] "C"  BMS
 SG_ t m99 : 32|16@1+ (0.1,0) [0|0] "C"  BMS
 SG_ t m100 : 32|16@1+ (0.1,0) [0|0] "C"  BMS
 SG_ t m101 : 32|16@1+ (0.1,0) [0|0] "C"  BMS
 SG_ t m102 : 32|16@1+ (0.1,0) [0|0] "C"  BMS
 SG_ t m103 : 32|16@1+ (0.1,0) [0|0] "C"  BMS
 SG_ t m104 : 32|16@1+ (0.1,0) [0|0] "C"  BMS
 SG_ t m105 : 32|16@1+ (0.1,0) [0|0] "C"  BMS
 SG_ t m106 : 32|16@1+ (0.1,0) [0|0] "C"  BMS
 SG_ t m107 : 32|16@1+ (0.1,0) [0|0] "C"  BMS
 SG_ t m108 : 32|16@1+ (0.1,0) [0|0] "C"  BMS
 SG_ t m109 : 32|16@1+ (0.1,0) [0|0] "C"  BMS
 SG_ t m110 : 32|16@1+ (0.1,0) [0|0] "C"  BMS
 SG_ t m111 : 32|16@1+ (0.1,0) [0|0] "C"  BMS
 SG_ t m112 : 32|16@1+ (0.1,0) [0|0] "C"  BMS
 SG_ t m113 : 32|16@1+ (0.1,0) [0|0] "C"  BMS
 SG_ t m114 : 32|16@1+ (0.1,0) [0|0] "C"  BMS
 SG_ t m115 : 32|16@1+ (0.1,0) [0|0] "C"  BMS
 SG_ t m116 : 32|16@1+ (0.1,0) [0|0] "C"  BMS
 SG_ t m117 : 32|16@1+ (0.1,0) [0|0] "C"  BMS
 SG_ t m118 : 32|16@1+ (0.1,0) [0|0] "C"  BMS
 SG_ t m119 : 32|16@1+ (0.1,0) [0|0] "C"  BMS
 SG_ t m120 : 32|16@1+ (0.1,0) [0|0] "C"  BMS
 SG_ t m121 : 32|16@1+ (0.1,0) [0|0] "C"  BMS
 SG_ t m122 : 32|16@1+ (0.1,0) [0|0] "C"  BMS
 SG_ t m123 : 32|16@1+ (0.1,0) [0|0] "C"  BMS
 SG_ t m124 : 32|16@1+ (0.1,0) [0|0] "C"  BMS
 SG_ t m125 : 32|16@1+ (0.1,0) [0|0] "C"  BMS
 SG_ t m126 : 32|16@1+ (0.1,0) [0|0] "C"  BMS
 SG_ t m127 : 32|16@1+ (0.1,0) [0|0] "C"  BMS
 SG_ t m128 : 32|16@1+ (0.1,0) [0|0] "C"  BMS
 SG_ t m129 : 32|16@1+ (0.1,0) [0|0] "C"  BMS
 SG_ t m130 : 32|16@1+ (0.1,0) [0|0] "C"  BMS
 SG_ t m131 : 32|16@1+ (0.1,0) [0|0] "C"  BMS
 SG_ t m132 : 32|16@1+ (0.1,0) [0|0] "C"  BMS
 SG_ t m133 : 32|16@1+ (0.1,0) [0|0] "C"  BMS
 SG_ t m134 : 32|16@1+ (0.1,0) [0|0] "C"  BMS
 SG_ t m135 : 32|16@1+ (0.1,0) [0|0] "C"  BMS
 SG_ t m136 : 32|16@1+ (0.1,0) [0|0] "C"  BMS
 SG_ t m137 : 32|16@1+ (0.1,0) [0|0] "C"  BMS
 SG_ t m138 : 32|16@1+ (0.1,0) [0|0] "C"  BMS
 SG_ t m139 : 32|16@1+ (0.1,0) [0|0] "C"  BMS
 SG_ t m140 : 32|16@1+ (0.1,0) [0|0] "C"  BMS
 SG_ t m141 : 32|16@1+ (0.1,0) [0|0] "C"  BMS
 SG_ t m142 : 32|16@1+ (0.1,0) [0|0] "C"  BMS
 SG_ t m143 : 32|16@1+ (0.1,0) [0|0] "C"  BMS
 SG_ soc m0 : 48|16@1+ (1,0) [0|0] "%"  BMS
 SG_ soc m1 : 48|16@1+ (1,0) [0|0] "%"  BMS
 SG_ soc m2 : 48|16@1+ (1,0) [0|0] "%"  BMS
 SG_ soc m3 : 48|16@1+ (1,0) [0|0] "%"  BMS
 SG_ soc m4 : 48|16@1+ (1,0) [0|0] "%"  BMS
 SG_ soc m5 : 48|16@1+ (1,0) [0|0] "%"  BMS
 SG_ soc m6 : 48|16@1+ (1,0) [0|0] "%"  BMS
 SG_ soc m7 : 48|16@1+ (1,0) [0|0] "%"  BMS
 SG_ soc m8 : 48|16@1+ (1,0) [0|0] "%"  BMS
 SG_ soc m9 : 48|16@1+ (1,0) [0|0] "%"  BMS
 SG_ soc m10 : 48|16@1+ (1,0) [0|0] "%"  BMS
 SG_ soc m11 : 48|16@1+ (1,0) [0|0] "%"  BMS
 SG_ soc m12 : 48|16@1+ (1,0) [0|0] "%"  BMS
 SG_ soc m13 : 48|16@1+ (1,0) [0|0] "%"  BMS
 SG_ soc m14 : 48|16@1+ (1,0) [0|0] "%"  BMS
 SG_ soc m15 : 48|16@1+ (1,0) [0|0] "%"  BMS
 SG_ soc m16 : 48|16@1+ (1,0) [0|0] "%"  BMS
 SG_ soc m17 : 48|16@1+ (1,0) [0|0] "%"  BMS
 SG_ soc m18 : 48|16@1+ (1,0) [0|0] "%"  BMS
 SG_ soc m19 : 48|16@1+ (1,0) [0|0] "%"  BMS
 SG_ soc m20 : 48|16@1+ (1,0) [0|0] "%"  BMS
 SG_ soc m21 : 48|16@1+ (1,0) [0|0] "%"  BMS
 SG_ soc m22 : 48|16@1+ (1,0) [0|0] "%"  BMS
 SG_ soc m23 : 48|16@1+ (1,0) [0|0] "%"  BMS
 SG_ soc m24 : 48|16@1+ (1,0) [0|0] "%"  BMS
 SG_ soc m25 : 48|16@1+ (1,0) [0|0] "%"  BMS
 SG_ soc m26 : 48|16@1+ (1,0) [0|0] "%"  BMS
 SG_ soc m27 : 48|16@1+ (1,0) [0|0] "%"  BMS
 SG_ soc m28 : 48|16@1+ (1,0) [0|0] "%"  BMS
 SG_ soc m29 : 48|16@1+ (1,0) [0|0] "%"  BMS
 SG_ soc m30 : 48|16@1+ (1,0) [0|0] "%"  BMS
 SG_ soc m31 : 48|16@1+ (1,0) [0|0] "%"  BMS
 SG_ soc m32 : 48|16@1+ (1,0) [0|0] "%"  BMS
 SG_ soc m33 : 48|16@1+ (1,0) [0|0] "%"  BMS
 SG_ soc m34 : 48|16@1+ (1,0) [0|0] "%"  BMS
 SG_ soc m35 : 48|16@1+ (1,0) [0|0] "%"  BMS
 SG_ soc m36 : 48|16@1+ (1,0) [0|0] "%"  BMS
 SG_ soc m37 : 48|16@1+ (1,0) [0|0] "%"  BMS
 SG_ soc m38 : 48|16@1+ (1,0) [0|0] "%"  BMS
 SG_ soc m39 : 48|16@1+ (1,0) [0|0] "%"  BMS
 SG_ soc m40 : 48|16@1+ (1,0) [0|0] "%"  BMS
 SG_ soc m41 : 48|16@1+ (1,0) [0|0] "%"  BMS
 SG_ soc m42 : 48|16@1+ (1,0) [0|0] "%"  BMS
 SG_ soc m43 : 48|16@1+ (1,0) [0|0] "%"  BMS
 SG_ soc m44 : 48|16@1+ (1,0) [0|0] "%"  BMS
 SG_ soc m45 : 48|16@1+ (1,0) [0|0] "%"  BMS
 SG_ soc m46 : 48|16@1+ (1,0) [0|0] "%"  BMS
 SG_ soc m47 : 48|16@1+ (1,0) [0|0] "%"  BMS
 SG_ soc m48 : 48|16@1+ (1,0) [0|0] "%"  BMS
 SG_ soc m49 : 48|16@1+ (1,0) [0|0] "%"  BMS
 SG_ soc m50 : 48|16@1+ (1,0) [0|0] "%"  BMS
 SG_ soc m51 : 48|16@1+ (1,0) [0|0] "%"  BMS
 SG_ soc m52 : 48|16@1+ (1,0) [0|0] "%"  BMS
 SG_ soc m53 : 48|16@1+ (1,0) [0|0] "%"  BMS
 SG_ soc m54 : 48|16@1+ (1,0) [0|0] "%"  BMS
 SG_ soc m55 : 48|16@1+ (1,0) [0|0] "%"  BMS
 SG_ soc m56 : 48|16@1+ (1,0) [0|0] "%"  BMS
 SG_ soc m57 : 48|16@1+ (1,0) [0|0] "%"  BMS
 SG_ soc m58 : 48|16@1+ (1,0) [0|0] "%"  BMS
 SG_ soc m59 : 48|16@1+ (1,0) [0|0] "%"  BMS
 SG_ soc m60 : 48|16@1+ (1,0) [0|0] "%"  BMS
 SG_ soc m61 : 48|16@1+ (1,0) [0|0] "%"  BMS
 SG_ soc m62 : 48|16@1+ (1,0) [0|0] "%"  BMS
 SG_ soc m63 : 48|16@1+ (1,0) [0|0] "%"  BMS
 SG_ soc m64 : 48|16@1+ (1,0) [0|0] "%"  BMS
 SG_ soc m65 : 48|16@1+ (1,0) [0|0] "%"  BMS
 SG_ soc m66 : 48|16@1+ (1,0) [0|0] "%"  BMS
 SG_ soc m67 : 48|16@1+ (1,0) [0|0] "%"  BMS
 SG_ soc m68 : 48|16@1+ (1,0) [0|0] "%"  BMS
 SG_ soc m69 : 48|16@1+ (1,0) [0|0] "%"  BMS
 SG_ soc m70 : 48|16@1+ (1,0) [0|0] "%"  BMS
 SG_ soc m71 : 48|16@1+ (1,0) [0|0] "%"  BMS
 SG_ soc m72 : 48|16@1+ (1,0) [0|0] "%"  BMS
 SG_ soc m73 : 48|16@1+ (1,0) [0|0] "%"  BMS
 SG_ soc m74 : 48|16@1+ (1,0) [0|0] "%"  BMS
 SG_ soc m75 : 48|16@1+ (1,0) [0|0] "%"  BMS
 SG_ soc m76 : 48|16@1+ (1,0) [0|0] "%"  BMS
 SG_ soc m77 : 48|16@1+ (1,0) [0|0] "%"  BMS
 SG_ soc m78 : 48|16@1+ (1,0) [0|0] "%"  BMS
 SG_ soc m79 : 48|16@1+ (1,0) [0|0] "%"  BMS
 SG_ soc m80 : 48|16@1+ (1,0) [0|0] "%"  BMS
 SG_ soc m81 : 48|16@1+ (1,0) [0|0] "%"  BMS
 SG_ soc m82 : 48|16@1+ (1,0) [0|0] "%"  BMS
 SG_ soc m83 : 48|16@1+ (1,0) [0|0] "%"  BMS
 SG_ soc m84 : 48|16@1+ (1,0) [0|0] "%"  BMS
 SG_ soc m85 : 48|16@1+ (1,0) [0|0] "%"  BMS
 SG_ soc m86 : 48|16@1+ (1,0) [0|0] "%"  BMS
 SG_ soc m87 : 48|16@1+ (1,0) [0|0] "%"  BMS
 SG_ soc m88 : 48|16@1+ (1,0) [0|0] "%"  BMS
 SG_ soc m89 : 48|16@1+ (1,0) [0|0] "%"  BMS
 SG_ soc m90 : 48|16@1+ (1,0) [0|0] "%"  BMS
 SG_ soc m91 : 48|16@1+ (1,0) [0|0] "%"  BMS
 SG_ soc m92 : 48|16@1+ (1,0) [0|0] "%"  BMS
 SG_ soc m93 : 48|16@1+ (1,0) [0|0] "%"  BMS
 SG_ soc m94 : 48|16@1+ (1,0) [0|0] "%"  BMS
 SG_ soc m95 : 48|16@1+ (1,0) [0|0] "%"  BMS
 SG_ soc m96 : 48|16@1+ (1,0) [0|0] "%"  BMS
 SG_ soc m97 : 48|16@1+ (1,0) [0|0] "%"  BMS
 SG_ soc m98 : 48|16@1+ (1,0) [0|0] "%"  BMS
 SG_ soc m99 : 48|16@1+ (1,0) [0|0] "%"  BMS
 SG_ soc m100 : 48|16@1+ (1,0) [0|0] "%"  BMS
 SG_ soc m101 : 48|16@1+ (1,0) [0|0] "%"  BMS
 SG_ soc m102 : 48|16@1+ (1,0) [0|0] "%"  BMS
 SG_ soc m103 : 48|16@1+ (1,0) [0|0] "%"  BMS
 SG_ soc m104 : 48|16@1+ (1,0) [0|0] "%"  BMS
 SG_ soc m105 : 48|16@1+ (1,0) [0|0] "%"  BMS
 SG_ soc m106 : 48|16@1+ (1,0) [0|0] "%"  BMS
 SG_ soc m107 : 48|16@1+ (1,0) [0|0] "%"  BMS
 SG_ soc m108 : 48|16@1+ (1,0) [0|0] "%"  BMS
 SG_ soc m109 : 48|16@1+ (1,0) [0|0] "%"  BMS
 SG_ soc m110 : 48|16@1+ (1,0) [0|0] "%"  BMS
 SG_ soc m111 : 48|16@1+ (1,0) [0|0] "%"  BMS
 SG_ soc m112 : 48|16@1+ (1,0) [0|0] "%"  BMS
 SG_ soc m113 : 48|16@1+ (1,0) [0|0] "%"  BMS
 SG_ soc m114 : 48|16@1+ (1,0) [0|0] "%"  BMS
 SG_ soc m115 : 48|16@1+ (1,0) [0|0] "%"  BMS
 SG_ soc m116 : 48|16@1+ (1,0) [0|0] "%"  BMS
 SG_ soc m117 : 48|16@1+ (1,0) [0|0] "%"  BMS
 SG_ soc m118 : 48|16@1+ (1,0) [0|0] "%"  BMS
 SG_ soc m119 : 48|16@1+ (1,0) [0|0] "%"  BMS
 SG_ soc m120 : 48|16@1+ (1,0) [0|0] "%"  BMS
 SG_ soc m121 : 48|16@1+ (1,0) [0|0] "%"  BMS
 SG_ soc m122 : 48|16@1+ (1,0) [0|0] "%"  BMS
 SG_ soc m123 : 48|16@1+ (1,0) [0|0] "%"  BMS
 SG_ soc m124 : 48|16@1+ (1,0) [0|0] "%"  BMS
 SG_ soc m125 : 48|16@1+ (1,0) [0|0] "%"  BMS
 SG_ soc m126 : 48|16@1+ (1,0) [0|0] "%"  BMS
 SG_ soc m127 : 48|16@1+ (1,0) [0|0] "%"  BMS
 SG_ soc m128 : 48|16@1+ (1,0) [0|0] "%"  BMS
 SG_ soc m129 : 48|16@1+ (1,0) [0|0] "%"  BMS
 SG_ soc m130 : 48|16@1+ (1,0) [0|0] "%"  BMS
 SG_ soc m131 : 48|16@1+ (1,0) [0|0] "%"  BMS
 SG_ soc m132 : 48|16@1+ (1,0) [0|0] "%"  BMS
 SG_ soc m133 : 48|16@1+ (1,0) [0|0] "%"  BMS
 SG_ soc m134 : 48|16@1+ (1,0) [0|0] "%"  BMS
 SG_ soc m135 : 48|16@1+ (1,0) [0|0] "%"  BMS
 SG_ soc m136 : 48|16@1+ (1,0) [0|0] "%"  BMS
 SG_ soc m137 : 48|16@1+ (1,0) [0|0] "%"  BMS
 SG_ soc m138 : 48|16@1+ (1,0) [0|0] "%"  BMS
 SG_ soc m139 : 48|16@1+ (1,0) [0|0] "%"  BMS
 SG_ soc m140 : 48|16@1+ (1,0) [0|0] "%"  BMS
 SG_ soc m141 : 48|16@1+ (1,0) [0|0] "%"  BMS
 SG_ soc m142 : 48|16@1+ (1,0) [0|0] "%"  BMS
 SG_ soc m143 : 48|16@1+ (1,0) [0|0] "%"  BMS

BO_ 1999 BMS_SLV_INF_1: 8 BMS
 SG_ info1_slave_id M: 0|16@1+ (1,0) [0|11] ""  BMS
 SG_ dschrg_ch_flt m0 : 16|16@1+ (1,0) [0|0] ""  BMS
 SG_ dschrg_ch_flt m1 : 16|16@1+ (1,0) [0|0] ""  BMS
 SG_ dschrg_ch_flt m2 : 16|16@1+ (1,0) [0|0] ""  BMS
 SG_ dschrg_ch_flt m3 : 16|16@1+ (1,0) [0|0] ""  BMS
 SG_ dschrg_ch_flt m4 : 16|16@1+ (1,0) [0|0] ""  BMS
 SG_ dschrg_ch_flt m5 : 16|16@1+ (1,0) [0|0] ""  BMS
 SG_ dschrg_ch_flt m6 : 16|16@1+ (1,0) [0|0] ""  BMS
 SG_ dschrg_ch_flt m7 : 16|16@1+ (1,0) [0|0] ""  BMS
 SG_ dschrg_ch_flt m8 : 16|16@1+ (1,0) [0|0] ""  BMS
 SG_ dschrg_ch_flt m9 : 16|16@1+ (1,0) [0|0] ""  BMS
 SG_ dschrg_ch_flt m10 : 16|16@1+ (1,0) [0|0] ""  BMS
 SG_ dschrg_ch_flt m11 : 16|16@1+ (1,0) [0|0] ""  BMS
 SG_ cll_conn_flt m0 : 32|16@1+ (1,0) [0|0] ""  BMS
 SG_ cll_conn_flt m1 : 32|16@1+ (1,0) [0|0] ""  BMS
 SG_ cll_conn_flt m2 : 32|16@1+ (1,0) [0|0] ""  BMS
 SG_ cll_conn_flt m3 : 32|16@1+ (1,0) [0|0] ""  BMS
 SG_ cll_conn_flt m4 : 32|16@1+ (1,0) [0|0] ""  BMS
 SG_ cll_conn_flt m5 : 32|16@1+ (1,0) [0|0] ""  BMS
 SG_ cll_conn_flt m6 : 32|16@1+ (1,0) [0|0] ""  BMS
 SG_ cll_conn_flt m7 : 32|16@1+ (1,0) [0|0] ""  BMS
 SG_ cll_conn_flt m8 : 32|16@1+ (1,0) [0|0] ""  BMS
 SG_ cll_conn_flt m9 : 32|16@1+ (1,0) [0|0] ""  BMS
 SG_ cll_conn_flt m10 : 32|16@1+ (1,0) [0|0] ""  BMS
 SG_ cll_conn_flt m11 : 32|16@1+ (1,0) [0|0] ""  BMS
 SG_ cll_t_flt m0 : 48|12@1+ (1,0) [0|0] ""  BMS
 SG_ cll_t_flt m1 : 48|12@1+ (1,0) [0|0] ""  BMS
 SG_ cll_t_flt m2 : 48|12@1+ (1,0) [0|0] ""  BMS
 SG_ cll_t_flt m3 : 48|12@1+ (1,0) [0|0] ""  BMS
 SG_ cll_t_flt m4 : 48|12@1+ (1,0) [0|0] ""  BMS
 SG_ cll_t_flt m5 : 48|12@1+ (1,0) [0|0] ""  BMS
 SG_ cll_t_flt m6 : 48|12@1+ (1,0) [0|0] ""  BMS
 SG_ cll_t_flt m7 : 48|12@1+ (1,0) [0|0] ""  BMS
 SG_ cll_t_flt m8 : 48|12@1+ (1,0) [0|0] ""  BMS
 SG_ cll_t_flt m9 : 48|12@1+ (1,0) [0|0] ""  BMS
 SG_ cll_t_flt m10 : 48|12@1+ (1,0) [0|0] ""  BMS
 SG_ cll_t_flt m11 : 48|12@1+ (1,0) [0|0] ""  BMS
 SG_ slv_t1_flt m0 : 60|1@1+ (1,0) [0|0] ""  BMS
 SG_ slv_t1_flt m1 : 60|1@1+ (1,0) [0|0] ""  BMS
 SG_ slv_t1_flt m2 : 60|1@1+ (1,0) [0|0] ""  BMS
 SG_ slv_t1_flt m3 : 60|1@1+ (1,0) [0|0] ""  BMS
 SG_ slv_t1_flt m4 : 60|1@1+ (1,0) [0|0] ""  BMS
 SG_ slv_t1_flt m5 : 60|1@1+ (1,0) [0|0] ""  BMS
 SG_ slv_t1_flt m6 : 60|1@1+ (1,0) [0|0] ""  BMS
 SG_ slv_t1_flt m7 : 60|1@1+ (1,0) [0|0] ""  BMS
 SG_ slv_t1_flt m8 : 60|1@1+ (1,0) [0|0] ""  BMS
 SG_ slv_t1_flt m9 : 60|1@1+ (1,0) [0|0] ""  BMS
 SG_ slv_t1_flt m10 : 60|1@1+ (1,0) [0|0] ""  BMS
 SG_ slv_t1_flt m11 : 60|1@1+ (1,0) [0|0] ""  BMS
 SG_ slv_t2_flt m0 : 61|1@1+ (1,0) [0|0] ""  BMS
 SG_ slv_t2_flt m1 : 61|1@1+ (1,0) [0|0] ""  BMS
 SG_ slv_t2_flt m2 : 61|1@1+ (1,0) [0|0] ""  BMS
 SG_ slv_t2_flt m3 : 61|1@1+ (1,0) [0|0] ""  BMS
 SG_ slv_t2_flt m4 : 61|1@1+ (1,0) [0|0] ""  BMS
 SG_ slv_t2_flt m5 : 61|1@1+ (1,0) [0|0] ""  BMS
 SG_ slv_t2_flt m6 : 61|1@1+ (1,0) [0|0] ""  BMS
 SG_ slv_t2_flt m7 : 61|1@1+ (1,0) [0|0] ""  BMS
 SG_ slv_t2_flt m8 : 61|1@1+ (1,0) [0|0] ""  BMS
 SG_ slv_t2_flt m9 : 61|1@1+ (1,0) [0|0] ""  BMS
 SG_ slv_t2_flt m10 : 61|1@1+ (1,0) [0|0] ""  BMS
 SG_ slv_t2_flt m11 : 61|1@1+ (1,0) [0|0] ""  BMS
 SG_ htsnk_t1_flt m0 : 62|1@1+ (1,0) [0|0] ""  BMS
 SG_ htsnk_t1_flt m1 : 62|1@1+ (1,0) [0|0] ""  BMS
 SG_ htsnk_t1_flt m2 : 62|1@1+ (1,0) [0|0] ""  BMS
 SG_ htsnk_t1_flt m3 : 62|1@1+ (1,0) [0|0] ""  BMS
 SG_ htsnk_t1_flt m4 : 62|1@1+ (1,0) [0|0] ""  BMS
 SG_ htsnk_t1_flt m5 : 62|1@1+ (1,0) [0|0] ""  BMS
 SG_ htsnk_t1_flt m6 : 62|1@1+ (1,0) [0|0] ""  BMS
 SG_ htsnk_t1_flt m7 : 62|1@1+ (1,0) [0|0] ""  BMS
 SG_ htsnk_t1_flt m8 : 62|1@1+ (1,0) [0|0] ""  BMS
 SG_ htsnk_t1_flt m9 : 62|1@1+ (1,0) [0|0] ""  BMS
 SG_ htsnk_t1_flt m10 : 62|1@1+ (1,0) [0|0] ""  BMS
 SG_ htsnk_t1_flt m11 : 62|1@1+ (1,0) [0|0] ""  BMS
 SG_ htsnk_t2_flt m0 : 63|1@1+ (1,0) [0|0] ""  BMS
 SG_ htsnk_t2_flt m1 : 63|1@1+ (1,0) [0|0] ""  BMS
 SG_ htsnk_t2_flt m2 : 63|1@1+ (1,0) [0|0] ""  BMS
 SG_ htsnk_t2_flt m3 : 63|1@1+ (1,0) [0|0] ""  BMS
 SG_ htsnk_t2_flt m4 : 63|1@1+ (1,0) [0|0] ""  BMS
 SG_ htsnk_t2_flt m5 : 63|1@1+ (1,0) [0|0] ""  BMS
 SG_ htsnk_t2_flt m6 : 63|1@1+ (1,0) [0|0] ""  BMS
 SG_ htsnk_t2_flt m7 : 63|1@1+ (1,0) [0|0] ""  BMS
 SG_ htsnk_t2_flt m8 : 63|1@1+ (1,0) [0|0] ""  BMS
 SG_ htsnk_t2_flt m9 : 63|1@1+ (1,0) [0|0] ""  BMS
 SG_ htsnk_t2_flt m10 : 63|1@1+ (1,0) [0|0] ""  BMS
 SG_ htsnk_t2_flt m11 : 63|1@1+ (1,0) [0|0] ""  BMS

BO_ 1967 BMS_SLV_INF_2: 8 BMS
 SG_ info_slave_id M : 0|16@1+ (1,0) [0|11] ""  BMS
 SG_ dschrg_ch_st m0 : 16|16@1+ (1,0) [0|0] ""  BMS
 SG_ dschrg_ch_st m1 : 16|16@1+ (1,0) [0|0] ""  BMS
 SG_ dschrg_ch_st m2 : 16|16@1+ (1,0) [0|0] ""  BMS
 SG_ dschrg_ch_st m3 : 16|16@1+ (1,0) [0|0] ""  BMS
 SG_ dschrg_ch_st m4 : 16|16@1+ (1,0) [0|0] ""  BMS
 SG_ dschrg_ch_st m5 : 16|16@1+ (1,0) [0|0] ""  BMS
 SG_ dschrg_ch_st m6 : 16|16@1+ (1,0) [0|0] ""  BMS
 SG_ dschrg_ch_st m7 : 16|16@1+ (1,0) [0|0] ""  BMS
 SG_ dschrg_ch_st m8 : 16|16@1+ (1,0) [0|0] ""  BMS
 SG_ dschrg_ch_st m9 : 16|16@1+ (1,0) [0|0] ""  BMS
 SG_ dschrg_ch_st m10 : 16|16@1+ (1,0) [0|0] ""  BMS
 SG_ dschrg_ch_st m11 : 16|16@1+ (1,0) [0|0] ""  BMS
 SG_ htsnk_t1 m0 : 32|16@1+ (0.1,0) [0|0] "C"  BMS
 SG_ htsnk_t2 m0 : 48|8@1+ (0.1,0) [0|0] "C"  BMS
 SG_ htsnk_t1 m1 : 32|16@1+ (0.1,0) [0|0] "C"  BMS
 SG_ htsnk_t2 m1 : 48|8@1+ (0.1,0) [0|0] "C"  BMS
 SG_ htsnk_t1 m2 : 32|16@1+ (0.1,0) [0|0] "C"  BMS
 SG_ htsnk_t2 m2 : 48|8@1+ (0.1,0) [0|0] "C"  BMS
 SG_ htsnk_t1 m3 : 32|16@1+ (0.1,0) [0|0] "C"  BMS
 SG_ htsnk_t2 m3 : 48|8@1+ (0.1,0) [0|0] "C"  BMS
 SG_ htsnk_t1 m4 : 32|16@1+ (0.1,0) [0|0] "C"  BMS
 SG_ htsnk_t2 m4 : 48|8@1+ (0.1,0) [0|0] "C"  BMS
 SG_ htsnk_t1 m5 : 32|16@1+ (0.1,0) [0|0] "C"  BMS
 SG_ htsnk_t2 m5 : 48|8@1+ (0.1,0) [0|0] "C"  BMS
 SG_ htsnk_t1 m6 : 32|16@1+ (0.1,0) [0|0] "C"  BMS
 SG_ htsnk_t2 m6 : 48|8@1+ (0.1,0) [0|0] "C"  BMS
 SG_ htsnk_t1 m7 : 32|16@1+ (0.1,0) [0|0] "C"  BMS
 SG_ htsnk_t2 m7 : 48|8@1+ (0.1,0) [0|0] "C"  BMS
 SG_ htsnk_t1 m8 : 32|16@1+ (0.1,0) [0|0] "C"  BMS
 SG_ htsnk_t2 m8 : 48|8@1+ (0.1,0) [0|0] "C"  BMS
 SG_ htsnk_t1 m9 : 32|16@1+ (0.1,0) [0|0] "C"  BMS
 SG_ htsnk_t2 m9 : 48|8@1+ (0.1,0) [0|0] "C"  BMS
 SG_ htsnk_t1 m10 : 32|16@1+ (0.1,0) [0|0] "C"  BMS
 SG_ htsnk_t2 m10 : 49|8@1+ (0.1,0) [0|0] "C"  BMS
 SG_ htsnk_t1 m11 : 32|16@1+ (0.1,0) [0|0] "C"  BMS
 SG_ htsnk_t2 m11 : 50|8@1+ (0.1,0) [0|0] "C"  BMS

BO_ 1935 BMS_SLV_INF_3: 8 BMS
 SG_ info3_slave_id M : 0|8@1+ (1,0) [0|11] ""  BMS
 SG_ slv_t1 m0 : 16|16@1+ (0.1,0) [0|0] "C"  BMS
 SG_ slv_t1 m1 : 16|16@1+ (0.1,0) [0|0] "C"  BMS
 SG_ slv_t1 m2 : 16|16@1+ (0.1,0) [0|0] "C"  BMS
 SG_ slv_t1 m3 : 16|16@1+ (0.1,0) [0|0] "C"  BMS
 SG_ slv_t1 m4 : 16|16@1+ (0.1,0) [0|0] "C"  BMS
 SG_ slv_t1 m5 : 16|16@1+ (0.1,0) [0|0] "C"  BMS
 SG_ slv_t1 m6 : 16|16@1+ (0.1,0) [0|0] "C"  BMS
 SG_ slv_t1 m7 : 16|16@1+ (0.1,0) [0|0] "C"  BMS
 SG_ slv_t1 m8 : 16|16@1+ (0.1,0) [0|0] "C"  BMS
 SG_ slv_t1 m9 : 16|16@1+ (0.1,0) [0|0] "C"  BMS
 SG_ slv_t1 m10 : 16|16@1+ (0.1,0) [0|0] "C"  BMS
 SG_ slv_t1 m11 : 16|16@1+ (0.1,0) [0|0] "C"  BMS
 SG_ slv_t2 m0 : 32|16@1+ (0.1,0) [0|0] "C"  BMS
 SG_ slv_t2 m1 : 32|16@1+ (0.1,0) [0|0] "C"  BMS
 SG_ slv_t2 m2 : 32|16@1+ (0.1,0) [0|0] "C"  BMS
 SG_ slv_t2 m3 : 32|16@1+ (0.1,0) [0|0] "C"  BMS
 SG_ slv_t2 m4 : 32|16@1+ (0.1,0) [0|0] "C"  BMS
 SG_ slv_t2 m5 : 32|16@1+ (0.1,0) [0|0] "C"  BMS
 SG_ slv_t2 m6 : 32|16@1+ (0.1,0) [0|0] "C"  BMS
 SG_ slv_t2 m7 : 32|16@1+ (0.1,0) [0|0] "C"  BMS
 SG_ slv_t2 m8 : 32|16@1+ (0.1,0) [0|0] "C"  BMS
 SG_ slv_t2 m9 : 32|16@1+ (0.1,0) [0|0] "C"  BMS
 SG_ slv_t2 m10 : 32|16@1+ (0.1,0) [0|0] "C"  BMS
 SG_ slv_t2 m11 : 32|16@1+ (0.1,0) [0|0] "C"  BMS
 SG_ slv_t2 m12 : 32|16@1+ (0.1,0) [0|0] "C"  BMS
 SG_ BM_t m0 : 48|16@1+ (0.1,0) [0|0] "C"  BMS
 SG_ BM_t m1 : 48|16@1+ (0.1,0) [0|0] "C"  BMS
 SG_ BM_t m2 : 48|16@1+ (0.1,0) [0|0] "C"  BMS
 SG_ BM_t m3 : 48|16@1+ (0.1,0) [0|0] "C"  BMS
 SG_ BM_t m4 : 48|16@1+ (0.1,0) [0|0] "C"  BMS
 SG_ BM_t m5 : 48|16@1+ (0.1,0) [0|0] "C"  BMS
 SG_ BM_t m6 : 48|16@1+ (0.1,0) [0|0] "C"  BMS
 SG_ BM_t m7 : 48|16@1+ (0.1,0) [0|0] "C"  BMS
 SG_ BM_t m8 : 48|16@1+ (0.1,0) [0|0] "C"  BMS
 SG_ BM_t m9 : 48|16@1+ (0.1,0) [0|0] "C"  BMS
 SG_ BM_t m10 : 48|16@1+ (0.1,0) [0|0] "C"  BMS
 SG_ BM_t m11 : 48|16@1+ (0.1,0) [0|0] "C"  BMS
 SG_ BM_t m12 : 48|16@1+ (0.1,0) [0|0] "C"  BMS

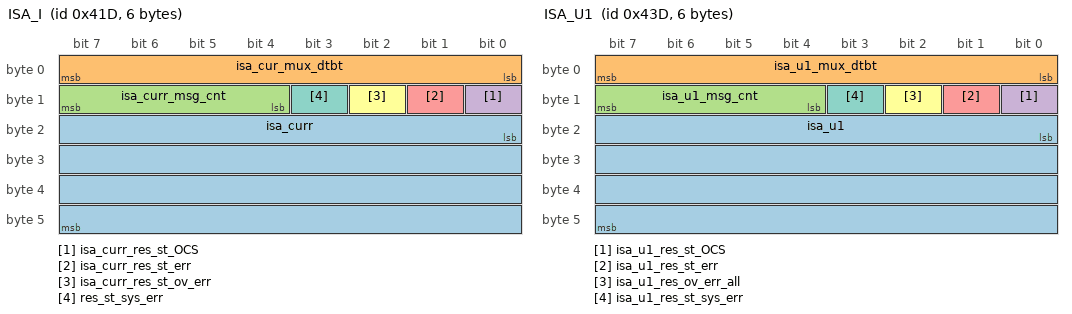
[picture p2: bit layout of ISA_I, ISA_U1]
BO_ 1053 ISA_I: 6 ISA
 SG_ isa_curr : 16|32@1- (1,0) [0|0] "mA"  ISA
 SG_ isa_cur_mux_dtbt : 0|8@1+ (1,0) [0|0] ""  ISA
 SG_ isa_curr_msg_cnt : 12|4@1+ (1,0) [0|0] ""  ISA
 SG_ isa_curr_res_st_OCS : 8|1@1+ (1,0) [0|0] ""  ISA
 SG_ isa_curr_res_st_err : 9|1@1+ (1,0) [0|0] ""  ISA
 SG_ isa_curr_res_st_ov_err : 10|1@1+ (1,0) [0|0] ""  ISA
 SG_ res_st_sys_err : 11|1@1+ (1,0) [0|0] ""  ISA

BO_ 1085 ISA_U1: 6 ISA
 SG_ isa_u1 : 16|32@1- (1,0) [0|0] "mV"  ISA
 SG_ isa_u1_mux_dtbt : 0|8@1+ (1,0) [0|0] ""  ISA
 SG_ isa_u1_msg_cnt : 12|4@1+ (1,0) [0|0] ""  ISA
 SG_ isa_u1_res_st_OCS : 8|1@1+ (1,0) [0|0] ""  ISA
 SG_ isa_u1_res_st_err : 9|1@1+ (1,0) [0|0] ""  ISA
 SG_ isa_u1_res_ov_err_all : 10|1@1+ (1,0) [0|0] ""  ISA
 SG_ isa_u1_res_st_sys_err : 11|1@1+ (1,0) [0|0] ""  ISA

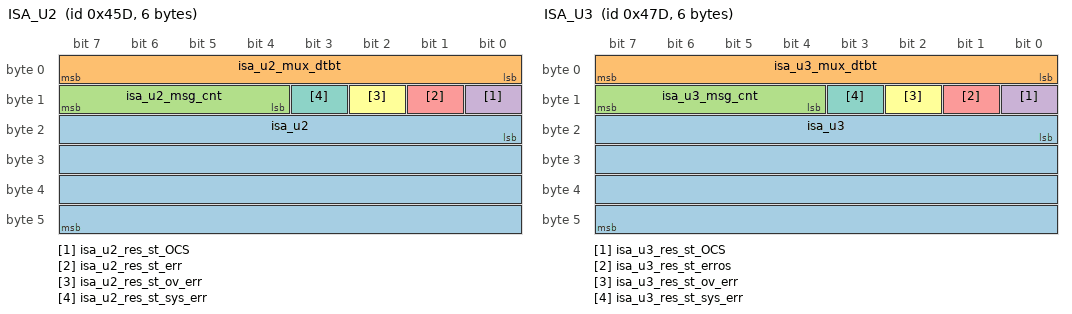
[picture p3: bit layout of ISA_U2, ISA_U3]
BO_ 1117 ISA_U2: 6 ISA
 SG_ isa_u2 : 16|32@1- (1,0) [0|0] "mV"  ISA
 SG_ isa_u2_mux_dtbt : 0|8@1+ (1,0) [0|0] ""  ISA
 SG_ isa_u2_msg_cnt : 12|4@1+ (1,0) [0|0] ""  ISA
 SG_ isa_u2_res_st_OCS : 8|1@1+ (1,0) [0|0] ""  ISA
 SG_ isa_u2_res_st_err : 9|1@1+ (1,0) [0|0] ""  ISA
 SG_ isa_u2_res_st_ov_err : 10|1@1+ (1,0) [0|0] ""  ISA
 SG_ isa_u2_res_st_sys_err : 11|1@1+ (1,0) [0|0] ""  ISA

BO_ 1149 ISA_U3: 6 ISA
 SG_ isa_u3 : 16|32@1- (1,0) [0|0] "mV"  ISA
 SG_ isa_u3_mux_dtbt : 0|8@1+ (1,0) [0|0] ""  ISA
 SG_ isa_u3_msg_cnt : 12|4@1+ (1,0) [0|0] ""  ISA
 SG_ isa_u3_res_st_OCS : 8|1@1+ (1,0) [0|0] ""  ISA
 SG_ isa_u3_res_st_erros : 9|1@1+ (1,0) [0|0] ""  ISA
 SG_ isa_u3_res_st_ov_err : 10|1@1+ (1,0) [0|0] ""  ISA
 SG_ isa_u3_res_st_sys_err : 11|1@1+ (1,0) [0|0] ""  ISA

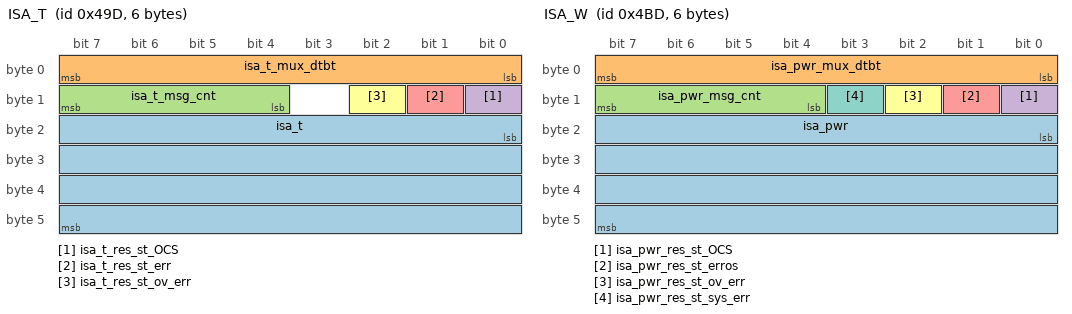
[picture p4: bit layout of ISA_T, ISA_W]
BO_ 1181 ISA_T: 6 ISA
 SG_ isa_t : 16|32@1- (1,0) [0|0] "0.1 �C"  ISA
 SG_ isa_t_mux_dtbt : 0|8@1+ (1,0) [0|0] ""  ISA
 SG_ isa_t_msg_cnt : 12|4@1+ (1,0) [0|0] ""  ISA
 SG_ isa_t_res_st_OCS : 8|1@1+ (1,0) [0|0] ""  ISA
 SG_ isa_t_res_st_err : 9|1@1+ (1,0) [0|0] ""  ISA
 SG_ isa_t_res_st_ov_err : 10|1@1+ (1,0) [0|0] ""  ISA

BO_ 1213 ISA_W: 6 ISA
 SG_ isa_pwr : 16|32@1- (1,0) [0|0] "W"  ISA
 SG_ isa_pwr_mux_dtbt : 0|8@1+ (1,0) [0|0] ""  ISA
 SG_ isa_pwr_msg_cnt : 12|4@1+ (1,0) [0|0] ""  ISA
 SG_ isa_pwr_res_st_OCS : 8|1@1+ (1,0) [0|0] ""  ISA
 SG_ isa_pwr_res_st_erros : 9|1@1+ (1,0) [0|0] ""  ISA
 SG_ isa_pwr_res_st_ov_err : 10|1@1+ (1,0) [0|0] ""  ISA
 SG_ isa_pwr_res_st_sys_err : 11|1@1+ (1,0) [0|0] ""  ISA

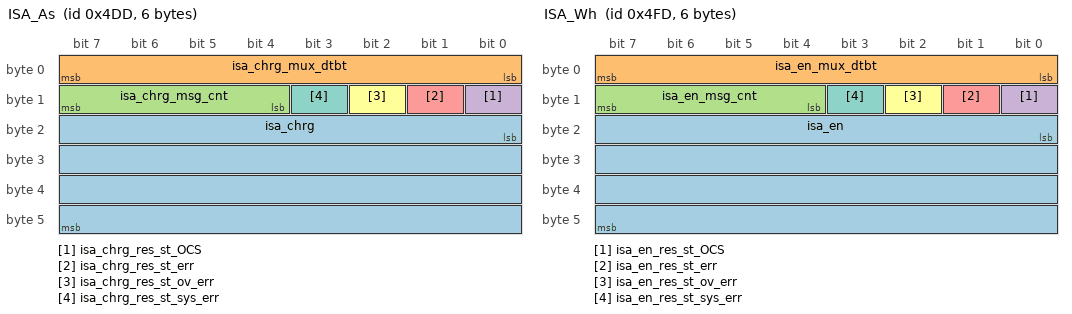
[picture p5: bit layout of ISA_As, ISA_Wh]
BO_ 1245 ISA_As: 6 ISA
 SG_ isa_chrg : 16|32@1- (1,0) [0|0] "As"  ISA
 SG_ isa_chrg_mux_dtbt : 0|8@1+ (1,0) [0|0] ""  ISA
 SG_ isa_chrg_msg_cnt : 12|4@1+ (1,0) [0|0] ""  ISA
 SG_ isa_chrg_res_st_OCS : 8|1@1+ (1,0) [0|0] ""  ISA
 SG_ isa_chrg_res_st_err : 9|1@1+ (1,0) [0|0] ""  ISA
 SG_ isa_chrg_res_st_ov_err : 10|1@1+ (1,0) [0|0] ""  ISA
 SG_ isa_chrg_res_st_sys_err : 11|1@1+ (1,0) [0|0] ""  ISA

BO_ 1277 ISA_Wh: 6 ISA
 SG_ isa_en : 16|32@1- (1,0) [0|0] "Wh"  ISA
 SG_ isa_en_mux_dtbt : 0|8@1+ (1,0) [0|0] ""  ISA
 SG_ isa_en_msg_cnt : 12|4@1+ (1,0) [0|0] ""  ISA
 SG_ isa_en_res_st_OCS : 8|1@1+ (1,0) [0|0] ""  ISA
 SG_ isa_en_res_st_err : 9|1@1+ (1,0) [0|0] ""  ISA
 SG_ isa_en_res_st_ov_err : 10|1@1+ (1,0) [0|0] ""  ISA
 SG_ isa_en_res_st_sys_err : 11|1@1+ (1,0) [0|0] ""  ISA

BO_ 1032 DCU_STATUS: 4 Vector__XXX
 SG_ status_det_sc_front_bspd : 0|1@1+ (1,0) [0|0] "" Vector__XXX
 SG_ det_sc_mh_front : 1|1@1+ (1,0) [0|0] "" Vector__XXX
 SG_ det_sc_bspd_ams : 2|1@1+ (1,0) [0|0] "" Vector__XXX
 SG_ det_sc_origin_mh : 3|1@1+ (1,0) [0|0] "" Vector__XXX
 SG_ det_vcc_ams : 4|1@1+ (1,0) [0|0] "" Vector__XXX
 SG_ stts_det_vcc_fans_ams : 5|1@1+ (1,0) [0|0] "" Vector__XXX
 SG_ stts_det_vcc_tsal : 6|1@1+ (1,0) [0|0] "" Vector__XXX
 SG_ stts_det_vcc_cua : 7|1@1+ (1,0) [0|0] "" Vector__XXX
 SG_ stts_det_vcc_cub : 8|1@1+ (1,0) [0|0] "" Vector__XXX
 SG_ stts_det_vcc_em : 9|1@1+ (1,0) [0|0] "" Vector__XXX
 SG_ stts_det_vcc_pumps : 10|1@1+ (1,0) [0|0] "" Vector__XXX
 SG_ stts_det_vcc_fans : 11|1@1+ (1,0) [0|0] "" Vector__XXX
 SG_ stts_det_vcc_cub2 : 12|1@1+ (1,0) [0|0] "" Vector__XXX
 SG_ stts_det_vcc_drs : 13|1@1+ (1,0) [0|0] "" Vector__XXX
 SG_ stts_det_vcc_can_e : 14|1@1+ (1,0) [0|0] "" Vector__XXX
 SG_ stts_det_vcc_bl : 15|1@1+ (1,0) [0|0] "" Vector__XXX
 SG_ stts_drsB_sig : 16|1@1+ (1,0) [0|0] "" Vector__XXX
 SG_ stts_drsF_sig : 17|1@1+ (1,0) [0|0] "" Vector__XXX
 SG_ stts_blue_sig : 18|1@1+ (1,0) [0|0] "" Vector__XXX
 SG_ stts_bl_sig : 20|1@1+ (1,0) [0|0] "" Vector__XXX
 SG_ stts_buzz_sig : 21|1@1+ (1,0) [0|0] "" Vector__XXX
 SG_ stts_dcdc_switch : 19|1@1+ (1,0) [0|0] "" Vector__XXX

BO_ 1064 DCU_DAQ: 6 DCU
 SG_ lv_current : 0|16@1+ (1,0) [0|0] "" Vector__XXX
 SG_ hv_current : 16|16@1+ (1,0) [0|0] "" Vector__XXX
 SG_ lv_voltage : 32|16@1+ (1,0) [0|0] "" Vector__XXX

BO_ 301 ARM_SETPOINTS: 8 Vector__XXX
 SG_ motor M : 0|16@1+ (1,0) [0|3] "" Vector__XXX
 SG_ speed m0 : 16|16@1+ (1,0) [0|0] "rpm" Vector__XXX
 SG_ t_pos m0 : 32|16@1- (0.001,0) [0|0] "Nm" Vector__XXX
 SG_ t_neg m0 : 48|16@1- (0.001,0) [0|0] "Nm" Vector__XXX
 SG_ speed m1 : 16|16@1+ (1,0) [0|0] "rpm" Vector__XXX
 SG_ t_pos m1 : 32|16@1- (0.001,0) [0|0] "Nm" Vector__XXX
 SG_ t_neg m1 : 48|16@1- (0.001,0) [0|0] "Nm" Vector__XXX
 SG_ speed m2 : 16|16@1+ (1,0) [0|0] "rpm" Vector__XXX
 SG_ t_pos m2 : 32|16@1- (0.001,0) [0|0] "Nm" Vector__XXX
 SG_ t_neg m2 : 48|16@1- (0.001,0) [0|0] "Nm" Vector__XXX
 SG_ speed m3 : 16|16@1+ (1,0) [0|0] "rpm" Vector__XXX
 SG_ t_pos m3 : 32|16@1- (0.001,0) [0|0] "Nm" Vector__XXX
 SG_ t_neg m3 : 48|16@1- (0.001,0) [0|0] "Nm" Vector__XXX

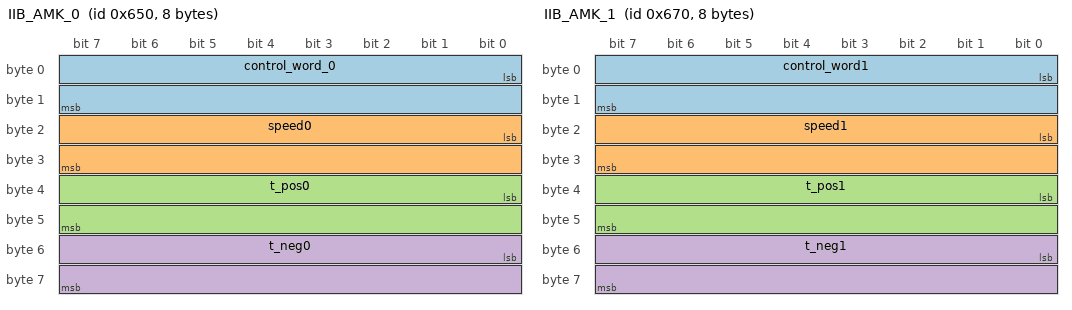
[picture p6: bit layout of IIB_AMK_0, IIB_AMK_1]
BO_ 1616 IIB_AMK_0: 8 Vector__XXX
 SG_ control_word_0 : 0|16@1+ (1,0) [0|0] "" Vector__XXX
 SG_ speed0 : 16|16@1+ (1,0) [0|0] "rpm" Vector__XXX
 SG_ t_pos0 : 32|16@1+ (0.0098,0) [0|0] "Nm" Vector__XXX
 SG_ t_neg0 : 48|16@1- (0.0098,0) [0|0] "Nm" Vector__XXX

BO_ 1648 IIB_AMK_1: 8 Vector__XXX
 SG_ control_word1 : 0|16@1+ (1,0) [0|0] "" Vector__XXX
 SG_ speed1 : 16|16@1+ (1,0) [0|0] "rpm" Vector__XXX
 SG_ t_pos1 : 32|16@1+ (0.0098,0) [0|0] "Nm" Vector__XXX
 SG_ t_neg1 : 48|16@1- (0.0098,0) [0|0] "Nm" Vector__XXX

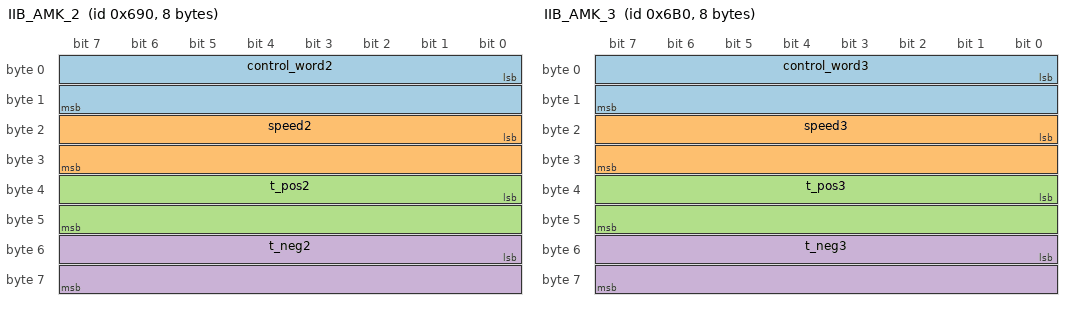
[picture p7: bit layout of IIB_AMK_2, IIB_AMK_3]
BO_ 1680 IIB_AMK_2: 8 Vector__XXX
 SG_ control_word2 : 0|16@1+ (1,0) [0|0] "" Vector__XXX
 SG_ speed2 : 16|16@1+ (1,0) [0|0] "rpm" Vector__XXX
 SG_ t_pos2 : 32|16@1+ (0.0098,0) [0|0] "Nm" Vector__XXX
 SG_ t_neg2 : 48|16@1- (0.0098,0) [0|0] "Nm" Vector__XXX

BO_ 1712 IIB_AMK_3: 8 Vector__XXX
 SG_ control_word3 : 0|16@1+ (1,0) [0|0] "" Vector__XXX
 SG_ speed3 : 16|16@1+ (1,0) [0|0] "rpm" Vector__XXX
 SG_ t_pos3 : 32|16@1+ (0.0098,0) [0|0] "Nm" Vector__XXX
 SG_ t_neg3 : 48|16@1- (0.0098,0) [0|0] "Nm" Vector__XXX

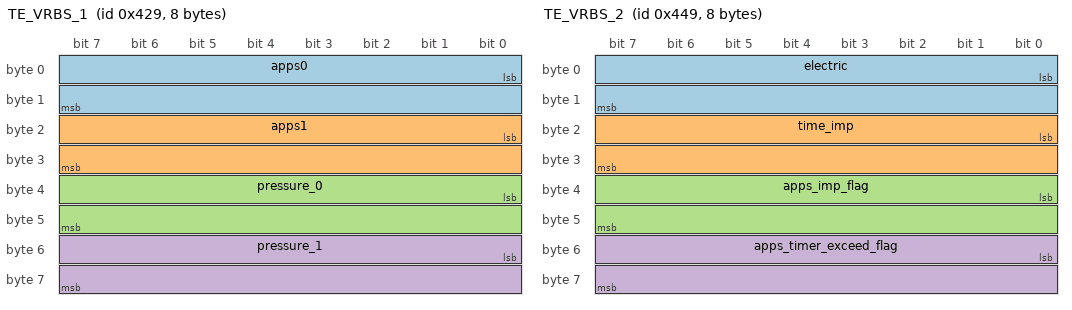
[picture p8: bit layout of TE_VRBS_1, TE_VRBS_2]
BO_ 1065 TE_VRBS_1: 8 Vector__XXX
 SG_ apps0 : 0|16@1+ (1,0) [0|0] "" Vector__XXX
 SG_ apps1 : 16|16@1+ (1,0) [0|0] "" Vector__XXX
 SG_ pressure_0 : 32|16@1+ (1,0) [0|0] "bar" Vector__XXX
 SG_ pressure_1 : 48|16@1+ (1,0) [0|0] "bar" Vector__XXX

BO_ 1097 TE_VRBS_2: 8 Vector__XXX
 SG_ electric : 0|16@1+ (1,0) [0|0] "" Vector__XXX
 SG_ time_imp : 16|16@1+ (1,0) [0|0] "" Vector__XXX
 SG_ apps_imp_flag : 32|16@1+ (1,0) [0|0] "" Vector__XXX
 SG_ apps_timer_exceed_flag : 48|16@1+ (1,0) [0|0] "" Vector__XXX

BO_ 1098 DASH_SE: 2 Vector__XXX
 SG_ angle : 0|16@1- (0.1,0) [0|0] "deg" Vector__XXX

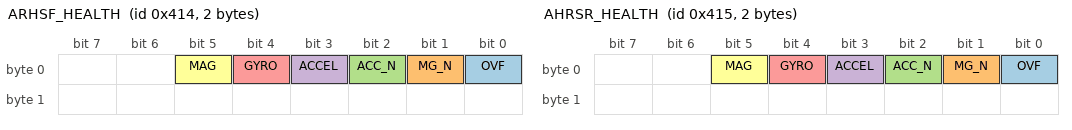
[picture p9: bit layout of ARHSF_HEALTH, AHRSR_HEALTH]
BO_ 1044 ARHSF_HEALTH: 2 Vector__XXX
 SG_ OVF : 0|1@1+ (1,0) [0|0] ""  AHRSF
 SG_ MG_N : 1|1@1+ (1,0) [0|0] ""  AHRSF
 SG_ ACC_N : 2|1@1+ (1,0) [0|0] ""  AHRSF
 SG_ ACCEL : 3|1@1+ (1,0) [0|0] ""  AHRSF
 SG_ GYRO : 4|1@1+ (1,0) [0|0] ""  AHRSF
 SG_ MAG : 5|1@1+ (1,0) [0|0] ""  AHRSF

BO_ 1045 AHRSR_HEALTH: 2 Vector__XXX
 SG_ OVF : 0|1@1+ (1,0) [0|0] ""  AHRSR
 SG_ MG_N : 1|1@1+ (1,0) [0|0] ""  AHRSR
 SG_ ACC_N : 2|1@1+ (1,0) [0|0] ""  AHRSR
 SG_ ACCEL : 3|1@1+ (1,0) [0|0] ""  AHRSR
 SG_ GYRO : 4|1@1+ (1,0) [0|0] ""  AHRSR
 SG_ MAG : 5|1@1+ (1,0) [0|0] ""  AHRSR

BO_ 1076 AHRSF_ACCEL_X: 4 Vector__XXX
 SG_ accel_x : 0|16@1- (0.01,0) [0|0] "m/s/s"  AHRSF
 SG_ time_accel_x : 16|16@1+ (0.01,0) [0|0] "s"  AHRSF

BO_ 1077 AHRSR_ACCEL_X: 4 Vector__XXX
 SG_ accel_x : 0|16@1- (1,0) [0|0] ""  AHRSR
 SG_ time_accel_x : 16|16@1+ (1,0) [0|0] ""  AHRSR

BO_ 1108 AHRSF_ACCEL_Y: 4 Vector__XXX
 SG_ accel_y : 0|16@1- (0.01,0) [0|0] "m/s/s"  AHRSF
 SG_ time_accel_y : 16|16@1+ (0.01,0) [0|0] "s"  AHRSF

BO_ 1109 AHRSR_ACCEL_Y: 4 Vector__XXX
 SG_ accel_y : 0|16@1- (1,0) [0|0] ""  AHRSR
 SG_ time_accel_y : 16|16@1+ (1,0) [0|0] ""  AHRSR

BO_ 1140 AHRSF_ACCEL_Z: 4 Vector__XXX
 SG_ accel_z : 0|16@1+ (0.01,0) [0|0] "m/s/s"  AHRSF
 SG_ time_accel_z : 16|16@1+ (0.01,0) [0|0] "s"  AHRSF

BO_ 1141 AHRSR_ACCEL_Z: 4 Vector__XXX
 SG_ accel_z : 0|16@1- (1,0) [0|0] ""  AHRSR
 SG_ time_accel_z : 16|16@1+ (1,0) [0|0] ""  AHRSR

BO_ 1172 AHRSF_GYRO_X: 4 Vector__XXX
 SG_ gyro_x : 0|16@1+ (0.01,0) [0|0] "�/s"  AHRSF
 SG_ time_gyro_x : 16|16@1+ (0.01,0) [0|0] "s"  AHRSF

BO_ 1173 AHRSR_GYRO_X: 4 Vector__XXX
 SG_ gyro_x : 0|16@1- (1,0) [0|0] ""  AHRSR
 SG_ time_gyro_x : 16|16@1+ (1,0) [0|0] ""  AHRSR

BO_ 1204 AHRSF_GYRO_Y: 4 Vector__XXX
 SG_ gyro_y : 0|16@1- (0.01,0) [0|0] "�/s"  AHRSF
 SG_ time_gyro_y : 16|16@1+ (0.01,0) [0|0] "s"  AHRSF

BO_ 1205 AHRSR_GYRO_Y: 4 Vector__XXX
 SG_ gyro_y : 0|16@1- (1,0) [0|0] ""  AHRSR
 SG_ time_gyro_y : 16|16@1+ (1,0) [0|0] ""  AHRSR

BO_ 1236 AHRSF_GYRO_Z: 4 Vector__XXX
 SG_ gyro_z : 0|16@1- (0.01,0) [0|0] "�/s"  AHRSF
 SG_ time_gyro_z : 16|16@1+ (0.01,0) [0|0] "s"  AHRSF

BO_ 1237 AHRSR_GYRO_Z: 4 Vector__XXX
 SG_ gyro_z : 0|16@1- (1,0) [0|0] ""  AHRSF
 SG_ time_gyro_z : 16|16@1+ (1,0) [0|0] ""  AHRSF

BO_ 1268 AHRSF_ROLL: 4 Vector__XXX
 SG_ roll : 0|16@1- (1,0) [0|0] ""  AHRSF
 SG_ time_roll : 16|16@1+ (1,0) [0|0] ""  AHRSF

BO_ 1269 AHRSR_ROLL: 4 Vector__XXX
 SG_ roll : 0|16@1- (1,0) [0|0] ""  AHRSR
 SG_ time_roll : 16|16@1+ (0.01,0) [0|0] "s"  AHRSR

BO_ 1300 AHRSF_PITCH: 4 Vector__XXX
 SG_ pitch : 0|16@1- (1,0) [0|0] ""  AHRSF
 SG_ time_pitch : 16|16@1+ (1,0) [0|0] ""  AHRSF

BO_ 1301 AHRSR_PITCH: 4 Vector__XXX
 SG_ pitch : 0|16@1- (1,0) [0|0] ""  AHRSR
 SG_ time_pitch : 16|16@1+ (0.01,0) [0|0] "s"  AHRSR

BO_ 1332 AHRSF_YAW: 4 Vector__XXX
 SG_ yaw : 0|16@1- (1,0) [0|0] ""  AHRSF
 SG_ time_yaw : 16|16@1+ (1,0) [0|0] ""  AHRSF

BO_ 1333 AHRSR_YAW: 4 Vector__XXX
 SG_ yaw : 0|16@1- (0.01,0) [0|0] "s"  AHRSR
 SG_ time_yaw : 16|16@1+ (1,0) [0|0] ""  AHRSR

BO_ 1364 AHRSF_ROLL_RATE: 4 Vector__XXX
 SG_ roll_rate : 0|16@1- (1,0) [0|0] ""  AHRSF
 SG_ time_roll_rate : 16|16@1+ (1,0) [0|0] ""  AHRSF

BO_ 1365 AHRSR_ROLL_RATE: 4 Vector__XXX
 SG_ roll_rate : 0|16@1- (1,0) [0|0] ""  AHRSR
 SG_ time_roll_rate : 16|16@1+ (0.01,0) [0|0] "s"  AHRSR

BO_ 1396 AHRSF_PITCH_RATE: 4 Vector__XXX
 SG_ pitch_rate : 0|16@1- (1,0) [0|0] ""  AHRSF
 SG_ time_pitch_rate : 16|16@1+ (1,0) [0|0] ""  AHRSF

BO_ 1397 AHRSR_PITCH_RATE: 4 Vector__XXX
 SG_ pitch_rate : 0|16@1- (1,0) [0|0] ""  AHRSF
 SG_ time_pitch_rate : 16|16@1+ (0.01,0) [0|0] "s"  AHRSF

BO_ 1428 AHRSF_YAW_RATE: 4 Vector__XXX
 SG_ yaw_rate : 0|16@1- (1,0) [0|0] ""  AHRSF
 SG_ time_yaw_rate : 16|16@1+ (1,0) [0|0] ""  AHRSF

BO_ 1429 AHRSR_YAW_RATE: 4 Vector__XXX
 SG_ yaw_rate : 0|16@1- (0.01,0) [0|0] "s"  AHRSR
 SG_ time_yaw_rate : 16|16@1+ (1,0) [0|0] ""  AHRSR

BO_ 1046 GPSF_DATE: 6 Vector__XXX
 SG_ day : 0|16@1+ (1,0) [0|0] ""  GPSF
 SG_ month : 16|16@1+ (1,0) [0|0] ""  GPSF
 SG_ year : 32|16@1+ (1,0) [0|0] ""  GPSF

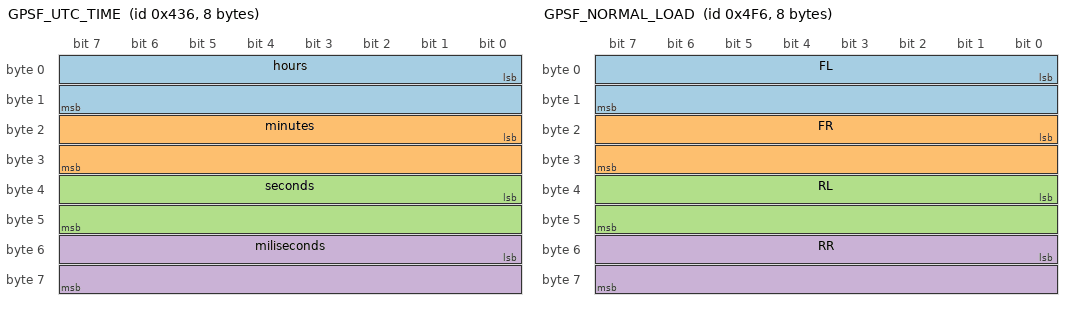
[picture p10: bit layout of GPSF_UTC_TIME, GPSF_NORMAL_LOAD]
BO_ 1078 GPSF_UTC_TIME: 8 Vector__XXX
 SG_ hours : 0|16@1+ (1,0) [0|0] ""  GPSF
 SG_ minutes : 16|16@1+ (1,0) [0|0] ""  GPSF
 SG_ seconds : 32|16@1+ (1,0) [0|0] ""  GPSF
 SG_ miliseconds : 48|16@1+ (1,0) [0|0] ""  GPSF

BO_ 1110 GPSF_LATITUDE: 6 Vector__XXX
 SG_ dg : 0|16@1- (1,0) [0|0] ""  GPSF
 SG_ min : 16|16@1+ (1,0) [0|0] ""  GPSF
 SG_ dec_min : 32|16@1+ (1,0) [0|0] ""  GPSF

BO_ 1142 GPSF_LONGITUDE: 6 Vector__XXX
 SG_ dg : 0|16@1- (1,0) [0|0] ""  GPSF
 SG_ min : 16|16@1+ (1,0) [0|0] ""  GPSF
 SG_ dec_min : 32|16@1+ (1,0) [0|0] ""  GPSF

BO_ 1174 GPSF_GROUND_SPEED: 2 Vector__XXX
 SG_ ground_speed : 0|16@1+ (1,0) [0|0] ""  GPSF

BO_ 1206 GPSF_POT_ADC_VALUE: 4 Vector__XXX
 SG_ pot1 : 0|16@1+ (1,0) [0|0] ""  GPSF
 SG_ pot2 : 16|16@1+ (1,0) [0|0] ""  GPSF

BO_ 1238 GPSF_SUPOTS_VELOCITY: 2 Vector__XXX
 SG_ velocity : 0|16@1+ (1,0) [0|0] ""  GPSF

BO_ 1270 GPSF_NORMAL_LOAD: 8 Vector__XXX
 SG_ FL : 0|16@1+ (1,0) [0|0] ""  GPSF
 SG_ FR : 16|16@1+ (1,0) [0|0] ""  GPSF
 SG_ RL : 32|16@1+ (1,0) [0|0] ""  GPSF
 SG_ RR : 48|16@1+ (1,0) [0|0] ""  GPSF

BO_ 1047 GPSR_DATE: 6 Vector__XXX
 SG_ day : 0|16@1+ (1,0) [0|0] ""  GPSR
 SG_ month : 16|16@1+ (1,0) [0|0] ""  GPSR
 SG_ year : 32|16@1+ (1,0) [0|0] ""  GPSR

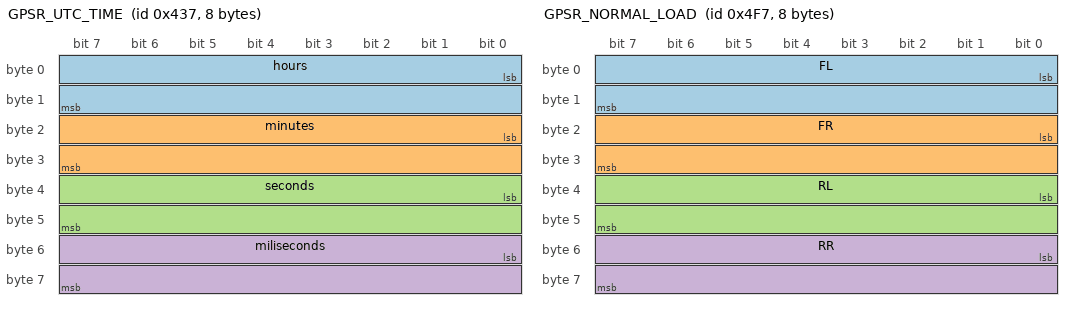
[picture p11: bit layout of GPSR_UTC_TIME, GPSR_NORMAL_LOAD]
BO_ 1079 GPSR_UTC_TIME: 8 Vector__XXX
 SG_ hours : 0|16@1+ (1,0) [0|0] ""  GPSR
 SG_ minutes : 16|16@1+ (1,0) [0|0] ""  GPSR
 SG_ seconds : 32|16@1+ (1,0) [0|0] ""  GPSR
 SG_ miliseconds : 48|16@1+ (1,0) [0|0] ""  GPSR

BO_ 1111 GPSR_LATITUDE: 6 Vector__XXX
 SG_ dg : 0|16@1- (1,0) [0|0] ""  GPSR
 SG_ min : 16|16@1+ (1,0) [0|0] ""  GPSR
 SG_ dec_min : 32|16@1+ (1,0) [0|0] ""  GPSR

BO_ 1143 GPSR_LONGITUDE: 6 Vector__XXX
 SG_ dg : 0|16@1- (1,0) [0|0] ""  GPSR
 SG_ min : 16|16@1+ (1,0) [0|0] ""  GPSR
 SG_ dec_min : 32|16@1+ (1,0) [0|0] ""  GPSR

BO_ 1175 GPSR_GROUND_SPEED: 2 Vector__XXX
 SG_ ground_speed : 0|16@1+ (1,0) [0|0] ""  GPSR

BO_ 1207 GPSR_POT_ADC_VALUE: 4 Vector__XXX
 SG_ pot1 : 0|16@1+ (1,0) [0|0] ""  GPSR
 SG_ pot2 : 16|16@1+ (1,0) [0|0] ""  GPSR

BO_ 1239 GPSR_SUPOTS_VELOCITY: 2 Vector__XXX
 SG_ velocity : 0|16@1+ (1,0) [0|0] ""  GPSR

BO_ 1271 GPSR_NORMAL_LOAD: 8 Vector__XXX
 SG_ FL : 0|16@1+ (1,0) [0|0] ""  GPSR
 SG_ FR : 16|16@1+ (1,0) [0|0] ""  GPSR
 SG_ RL : 32|16@1+ (1,0) [0|0] ""  GPSR
 SG_ RR : 48|16@1+ (1,0) [0|0] ""  GPSR

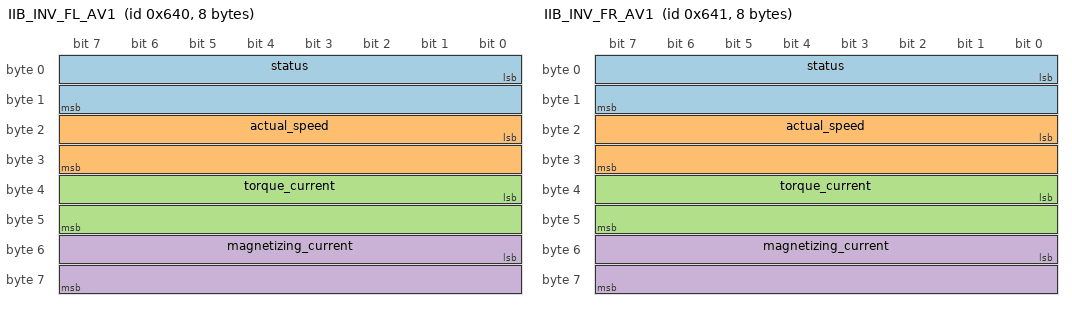
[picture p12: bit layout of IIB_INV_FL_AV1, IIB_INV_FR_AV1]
BO_ 1600 IIB_INV_FL_AV1: 8 Vector__XXX
 SG_ status : 0|16@1+ (1,0) [0|0] "" Vector__XXX
 SG_ actual_speed : 16|16@1- (1,0) [0|0] "rpm" Vector__XXX
 SG_ torque_current : 32|16@1- (0.00166625,0) [0|0] "Nm" Vector__XXX
 SG_ magnetizing_current : 48|16@1- (1,0) [0|0] "" Vector__XXX

BO_ 1601 IIB_INV_FR_AV1: 8 Vector__XXX
 SG_ status : 0|16@1+ (1,0) [0|0] "" Vector__XXX
 SG_ actual_speed : 16|16@1- (1,0) [0|0] "rpm" Vector__XXX
 SG_ torque_current : 32|16@1- (0.00166625,0) [0|0] "Nm" Vector__XXX
 SG_ magnetizing_current : 48|16@1- (1,0) [0|0] "" Vector__XXX

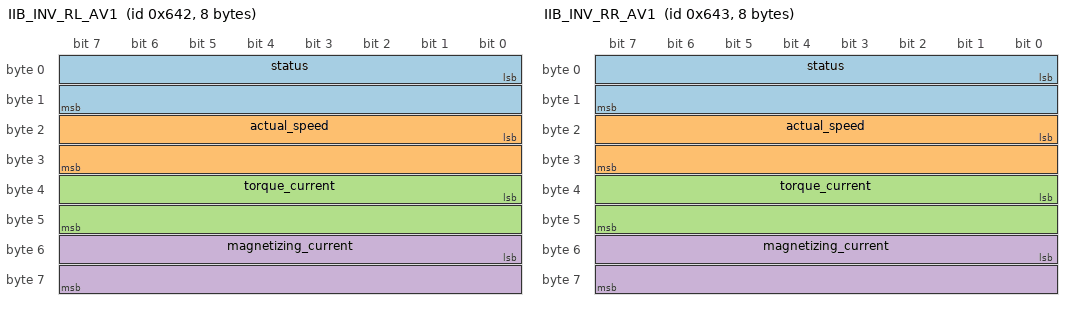
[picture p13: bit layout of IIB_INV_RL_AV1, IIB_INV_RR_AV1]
BO_ 1602 IIB_INV_RL_AV1: 8 Vector__XXX
 SG_ status : 0|16@1+ (1,0) [0|0] "" Vector__XXX
 SG_ actual_speed : 16|16@1- (1,0) [0|0] "rpm" Vector__XXX
 SG_ torque_current : 32|16@1- (0.00166625,0) [0|0] "Nm" Vector__XXX
 SG_ magnetizing_current : 48|16@1- (1,0) [0|0] "" Vector__XXX

BO_ 1603 IIB_INV_RR_AV1: 8 Vector__XXX
 SG_ status : 0|16@1+ (1,0) [0|0] "" Vector__XXX
 SG_ actual_speed : 16|16@1- (1,0) [0|0] "rpm" Vector__XXX
 SG_ torque_current : 32|16@1- (0.00166625,0) [0|0] "Nm" Vector__XXX
 SG_ magnetizing_current : 48|16@1- (1,0) [0|0] "" Vector__XXX

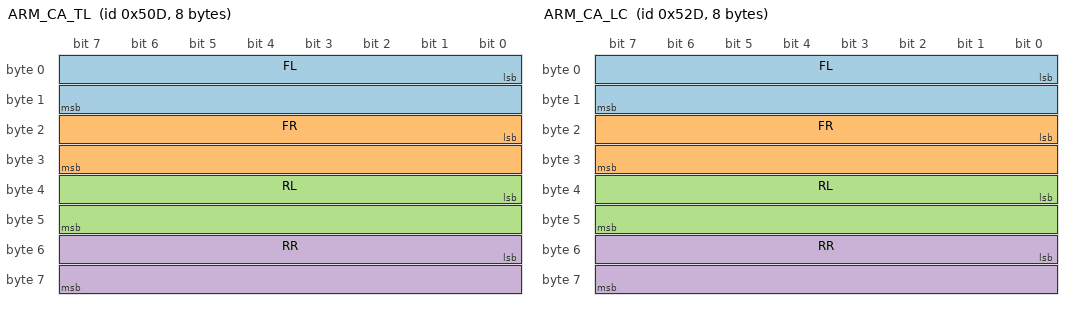
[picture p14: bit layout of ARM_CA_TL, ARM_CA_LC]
BO_ 1293 ARM_CA_TL: 8 Vector__XXX
 SG_ FL : 0|16@1- (0.001,0) [0|0] "Nm" Vector__XXX
 SG_ FR : 16|16@1- (0.001,0) [0|0] "Nm" Vector__XXX
 SG_ RL : 32|16@1- (0.001,0) [0|0] "Nm" Vector__XXX
 SG_ RR : 48|16@1- (0.001,0) [0|0] "Nm" Vector__XXX

BO_ 1037 ARM_DRS_ANGLE: 6 Vector__XXX
 SG_ Bottom_flap : 0|16@1+ (1,0) [0|0] "deg" Vector__XXX
 SG_ Top_flap : 16|16@1+ (1,0) [0|0] "deg" Vector__XXX
 SG_ State : 32|16@1+ (1,0) [0|0] "" Vector__XXX

BO_ 1133 ARM_STATUS: 2 Vector__XXX
 SG_ Control_OK : 0|8@1+ (1,0) [0|0] "" Vector__XXX

BO_ 1325 ARM_CA_LC: 8 Vector__XXX
 SG_ FL : 0|16@1- (0.001,0) [0|0] "N/m" Vector__XXX
 SG_ FR : 16|16@1- (0.001,0) [0|0] "N/m" Vector__XXX
 SG_ RL : 32|16@1- (0.001,0) [0|0] "N/m" Vector__XXX
 SG_ RR : 48|16@1- (0.001,0) [0|0] "N/m" Vector__XXX

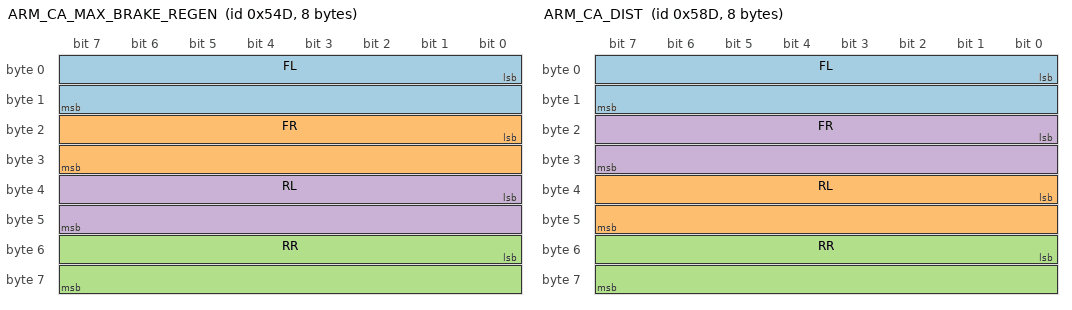
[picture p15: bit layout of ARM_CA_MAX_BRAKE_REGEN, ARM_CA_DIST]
BO_ 1357 ARM_CA_MAX_BRAKE_REGEN: 8 Vector__XXX
 SG_ FL : 0|16@1- (0.001,0) [0|0] "Nm" Vector__XXX
 SG_ FR : 16|16@1- (0.001,0) [0|0] "Nm" Vector__XXX
 SG_ RR : 48|16@1- (0.001,0) [0|0] "Nm" Vector__XXX
 SG_ RL : 32|16@1- (0.001,0) [0|0] "Nm" Vector__XXX

BO_ 1421 ARM_CA_DIST: 8 Vector__XXX
 SG_ FL : 0|16@1- (0.001,0) [0|0] "Nm" Vector__XXX
 SG_ RL : 32|16@1- (0.001,0) [0|0] "Nm" Vector__XXX
 SG_ RR : 48|16@1- (0.001,0) [0|0] "Nm" Vector__XXX
 SG_ FR : 16|16@1- (0.001,0) [0|0] "Nm" Vector__XXX

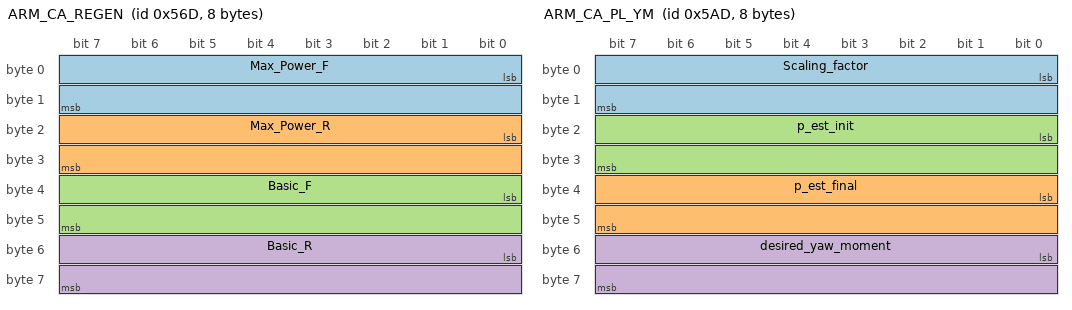
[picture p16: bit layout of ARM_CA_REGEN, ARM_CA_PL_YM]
BO_ 1389 ARM_CA_REGEN: 8 Vector__XXX
 SG_ Max_Power_F : 0|16@1- (0.001,0) [0|0] "Nm" Vector__XXX
 SG_ Max_Power_R : 16|16@1- (0.001,0) [0|0] "Nm" Vector__XXX
 SG_ Basic_F : 32|16@1- (0.001,0) [0|0] "Nm" Vector__XXX
 SG_ Basic_R : 48|16@1- (0.001,0) [0|0] "Nm" Vector__XXX

BO_ 1453 ARM_CA_PL_YM: 8 Vector__XXX
 SG_ Scaling_factor : 0|16@1- (0.001,0) [0|0] "" Vector__XXX
 SG_ p_est_final : 32|16@1- (10,0) [0|0] "" Vector__XXX
 SG_ p_est_init : 16|16@1- (10,0) [0|0] "" Vector__XXX
 SG_ desired_yaw_moment : 48|16@1+ (1,0) [0|0] "" Vector__XXX

BO_ 1997 ARM_DEBUG: 8 Vector__XXX
 SG_ accurate_est : 16|16@1- (10,0) [0|0] "" Vector__XXX
 SG_ power_error : 32|16@1- (10,0) [0|0] "" Vector__XXX
 SG_ remove_torque : 48|16@1- (1,0) [0|0] "" Vector__XXX

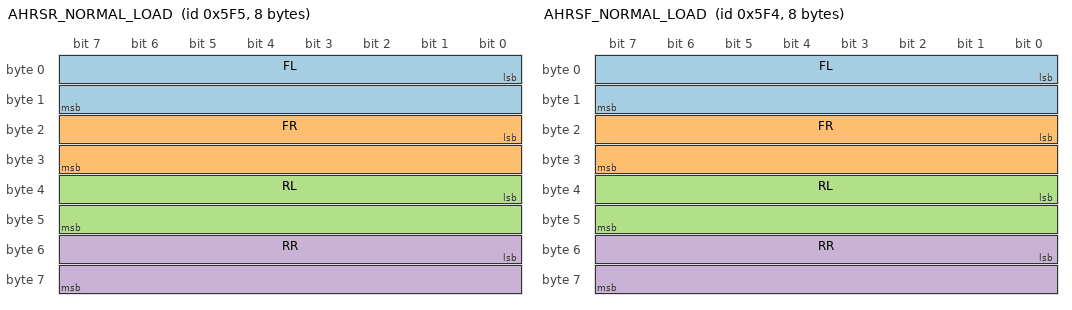
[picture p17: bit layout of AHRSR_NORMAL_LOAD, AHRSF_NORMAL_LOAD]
BO_ 1525 AHRSR_NORMAL_LOAD: 8 Vector__XXX
 SG_ FL : 0|16@1+ (1,0) [0|0] "" Vector__XXX
 SG_ FR : 16|16@1+ (1,0) [0|0] "" Vector__XXX
 SG_ RL : 32|16@1+ (1,0) [0|0] "" Vector__XXX
 SG_ RR : 48|16@1+ (1,0) [0|0] "" Vector__XXX

BO_ 1524 AHRSF_NORMAL_LOAD: 8 Vector__XXX
 SG_ FL : 0|16@1+ (1,0) [0|0] "" Vector__XXX
 SG_ FR : 16|16@1+ (1,0) [0|0] "" Vector__XXX
 SG_ RL : 32|16@1+ (1,0) [0|0] "" Vector__XXX
 SG_ RR : 48|16@1+ (1,0) [0|0] "" Vector__XXX

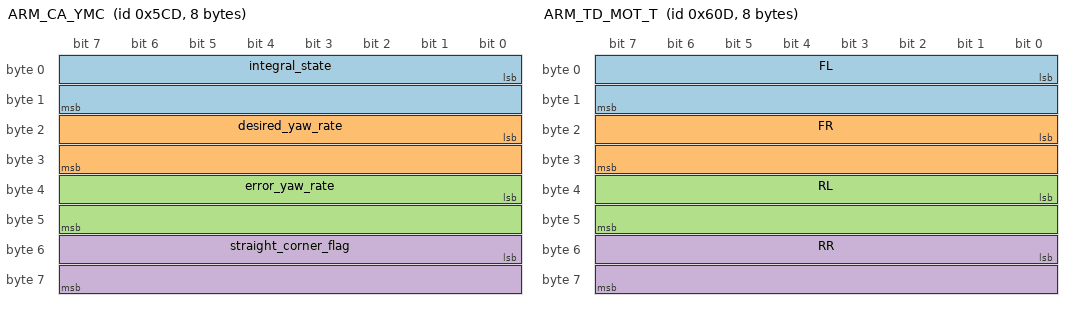
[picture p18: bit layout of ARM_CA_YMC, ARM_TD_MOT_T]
BO_ 1485 ARM_CA_YMC: 8 Vector__XXX
 SG_ integral_state : 0|16@1- (1,0) [0|0] "" Vector__XXX
 SG_ desired_yaw_rate : 16|16@1- (1,0) [0|0] "" Vector__XXX
 SG_ error_yaw_rate : 32|16@1- (1,0) [0|0] "" Vector__XXX
 SG_ straight_corner_flag : 48|16@1+ (1,0) [0|0] "" Vector__XXX

BO_ 1517 ARM_TD_INV_V: 4 Vector__XXX
 SG_ volt_charge : 0|16@1+ (1,0) [0|0] "" Vector__XXX
 SG_ volt_discharge : 16|16@1+ (1,0) [0|0] "" Vector__XXX

BO_ 1549 ARM_TD_MOT_T: 8 Vector__XXX
 SG_ FL : 0|16@1+ (0.001,0) [0|0] "Nm" Vector__XXX
 SG_ FR : 16|16@1+ (0.001,0) [0|0] "Nm" Vector__XXX
 SG_ RL : 32|16@1+ (0.001,0) [0|0] "Nm" Vector__XXX
 SG_ RR : 48|16@1+ (0.001,0) [0|0] "Nm" Vector__XXX

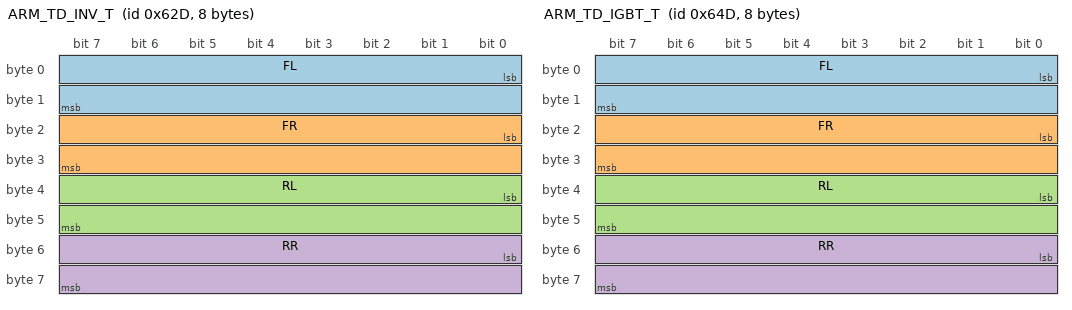
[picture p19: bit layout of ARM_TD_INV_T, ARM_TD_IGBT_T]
BO_ 1581 ARM_TD_INV_T: 8 Vector__XXX
 SG_ FL : 0|16@1+ (0.001,0) [0|0] "Nm" Vector__XXX
 SG_ FR : 16|16@1+ (0.001,0) [0|0] "Nm" Vector__XXX
 SG_ RL : 32|16@1+ (0.001,0) [0|0] "Nm" Vector__XXX
 SG_ RR : 48|16@1+ (0.001,0) [0|0] "Nm" Vector__XXX

BO_ 1613 ARM_TD_IGBT_T: 8 Vector__XXX
 SG_ FL : 0|16@1+ (0.001,0) [0|0] "Nm" Vector__XXX
 SG_ FR : 16|16@1+ (0.001,0) [0|0] "Nm" Vector__XXX
 SG_ RL : 32|16@1+ (0.001,0) [0|0] "Nm" Vector__XXX
 SG_ RR : 48|16@1+ (0.001,0) [0|0] "Nm" Vector__XXX

BO_ 1645 ARM_TD_MOT_P: 8 Vector__XXX
 SG_ FL : 0|16@1+ (0.001,0) [0|0] "Nm" Vector__XXX
 SG_ FR : 16|16@1+ (0.001,0) [0|0] "Nm" Vector__XXX
 SG_ RL : 32|16@1+ (0.001,0) [0|0] "Nm" Vector__XXX
 SG_ RR : 48|16@1+ (0.001,0) [0|0] "Nm" Vector__XXX

BO_ 1677 ARM_TD_I2T: 8 Vector__XXX
 SG_ FL : 0|16@1+ (0.001,0) [0|0] "Nm" Vector__XXX
 SG_ FR : 16|16@1+ (0.001,0) [0|0] "Nm" Vector__XXX
 SG_ RL : 32|16@1+ (0.001,0) [0|0] "Nm" Vector__XXX
 SG_ RR : 48|16@1+ (0.001,0) [0|0] "Nm" Vector__XXX

BO_ 1741 ARM_TD_NET: 8 Vector__XXX
 SG_ FL : 0|16@1+ (0.001,0) [0|0] "Nm" Vector__XXX
 SG_ FR : 16|16@1+ (0.001,0) [0|0] "Nm" Vector__XXX
 SG_ RL : 32|16@1+ (0.001,0) [0|0] "Nm" Vector__XXX
 SG_ RR : 48|16@1+ (0.001,0) [0|0] "Nm" Vector__XXX

BO_ 1709 ARM_PD: 8 Vector__XXX
 SG_ cell_temp_discharge : 0|16@1+ (1,0) [0|0] "" Vector__XXX
 SG_ cell_temp_charge : 16|16@1+ (1,0) [0|0] "" Vector__XXX
 SG_ cell_min_volt : 32|16@1+ (1,0) [0|0] "" Vector__XXX
 SG_ cell_max_volt : 48|16@1+ (1,0) [0|0] "" Vector__XXX

BO_ 1773 ARM_PD_NET: 8 Vector__XXX
 SG_ power_pos : 0|16@1+ (1,0) [0|0] "" Vector__XXX
 SG_ power_neg : 16|16@1+ (1,0) [0|0] "" Vector__XXX

BO_ 1805 ARM_I2T_VOL: 8 Vector__XXX
 SG_ FL : 0|16@1+ (1,0) [0|0] "" Vector__XXX
 SG_ FR : 16|16@1+ (1,0) [0|0] "" Vector__XXX
 SG_ RL : 32|16@1+ (1,0) [0|0] "" Vector__XXX
 SG_ RR : 48|16@1+ (1,0) [0|0] "" Vector__XXX

BO_ 1837 ARM_I2T_TRIG_TIME: 8 Vector__XXX
 SG_ FR : 16|16@1- (1,0) [0|0] "" Vector__XXX
 SG_ RL : 32|16@1- (1,0) [0|0] "" Vector__XXX
 SG_ RR : 48|16@1- (1,0) [0|0] "" Vector__XXX
 SG_ FL : 0|16@1- (1,0) [0|0] "" Vector__XXX

BO_ 1632 IIB_INV_FL_AV2: 8 Vector__XXX
 SG_ temp_motor : 0|16@1- (1,0) [0|0] "" Vector__XXX
 SG_ temp_inv : 16|16@1+ (1,0) [0|0] "" Vector__XXX
 SG_ error_info : 32|16@1+ (1,0) [0|0] "" Vector__XXX
 SG_ temp_igbt : 48|16@1+ (1,0) [0|0] "" Vector__XXX

BO_ 1633 IIB_INV_FR_AV2: 8 Vector__XXX
 SG_ temp_motor : 0|16@1- (1,0) [0|0] "" Vector__XXX
 SG_ temp_inv : 16|16@1+ (1,0) [0|0] "" Vector__XXX
 SG_ error_info : 32|16@1+ (1,0) [0|0] "" Vector__XXX
 SG_ temp_igbt : 48|16@1+ (1,0) [0|0] "" Vector__XXX

BO_ 1634 IIB_INV_RL_AV2: 8 Vector__XXX
 SG_ temp_motor : 0|16@1- (1,0) [0|0] "" Vector__XXX
 SG_ temp_inv : 16|16@1+ (1,0) [0|0] "" Vector__XXX
 SG_ error_info : 32|16@1+ (1,0) [0|0] "" Vector__XXX
 SG_ temp_igbt : 48|16@1+ (1,0) [0|0] "" Vector__XXX

BO_ 1635 IIB_INV_RR_AV2: 8 Vector__XXX
 SG_ temp_motor : 0|16@1- (1,0) [0|0] "" Vector__XXX
 SG_ temp_inv : 16|16@1+ (1,0) [0|0] "" Vector__XXX
 SG_ error_info : 32|16@1+ (1,0) [0|0] "" Vector__XXX
 SG_ temp_igbt : 48|16@1+ (1,0) [0|0] "" Vector__XXX

BO_ 1161 TE_BAR_PRESSURE: 8 Vector__XXX
 SG_ pressure0 : 0|16@1+ (0.1,0) [0|160] "bar" Vector__XXX
 SG_ pressure1 : 16|16@1+ (0.1,0) [0|160] "bar" Vector__XXX
